AUTOSAR XML (schema 4-2-2)
package /STELLANTIS/EPT/ASWCs
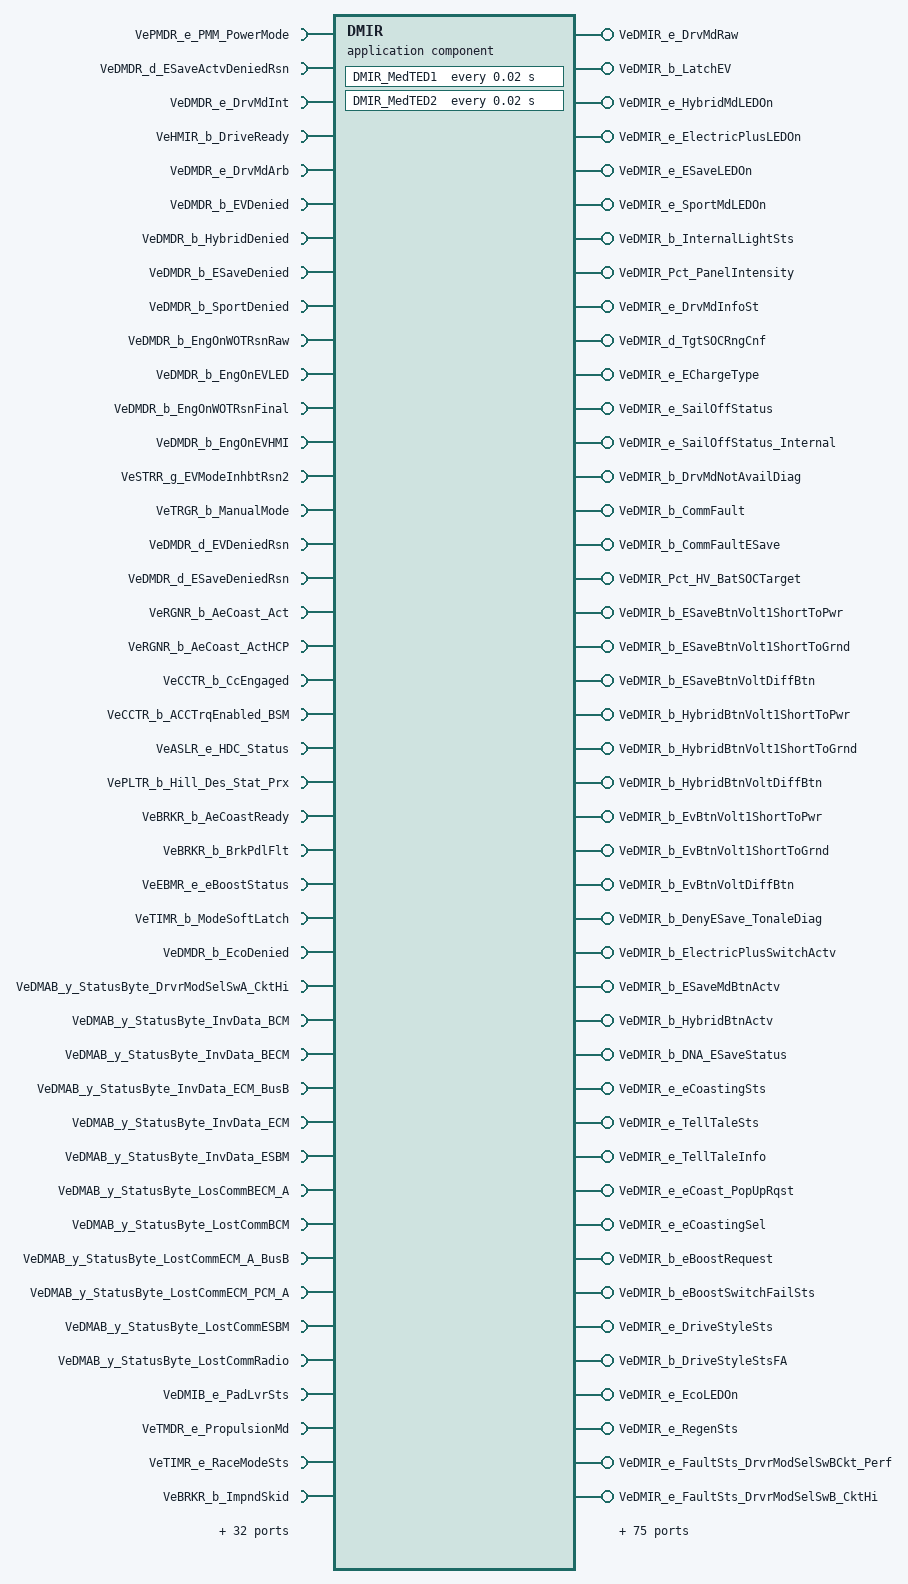
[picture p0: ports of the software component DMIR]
  application sw component type DMIR
    65 x require port:
      VePMDR_e_PMM_PowerMode: nonqueued-receiver-com-spec{data-element=Value, init-value=CePMDR_e_PowerMode_Off}, required-interface=VePMDR_e_PMM_PowerMode
      VeDMDR_d_ESaveActvDeniedRsn: nonqueued-receiver-com-spec{data-element=Value, init-value=0}, required-interface=VeDMDR_d_ESaveActvDeniedRsn
      VeDMDR_e_DrvMdInt: nonqueued-receiver-com-spec{data-element=Value, init-value=CeDMDR_e_NoDrvMd}, required-interface=VeDMDR_e_DrvMdInt
      VeHMIR_b_DriveReady: nonqueued-receiver-com-spec{data-element=Value, init-value=0}, required-interface=VeHMIR_b_DriveReady
      VeDMDR_e_DrvMdArb: nonqueued-receiver-com-spec{data-element=Value, init-value=CeDMDR_e_NoDrvMd}, required-interface=VeDMDR_e_DrvMdArb
      VeDMDR_b_EVDenied: nonqueued-receiver-com-spec{data-element=Value, init-value=0}, required-interface=VeDMDR_b_EVDenied
      VeDMDR_b_HybridDenied: nonqueued-receiver-com-spec{data-element=Value, init-value=0}, required-interface=VeDMDR_b_HybridDenied
      VeDMDR_b_ESaveDenied: nonqueued-receiver-com-spec{data-element=Value, init-value=0}, required-interface=VeDMDR_b_ESaveDenied
      VeDMDR_b_SportDenied: nonqueued-receiver-com-spec{data-element=Value, init-value=0}, required-interface=VeDMDR_b_SportDenied
      VeDMDR_b_EngOnWOTRsnRaw: nonqueued-receiver-com-spec{data-element=Value, init-value=0}, required-interface=VeDMDR_b_EngOnWOTRsnRaw
      VeDMDR_b_EngOnEVLED: nonqueued-receiver-com-spec{data-element=Value, init-value=0}, required-interface=VeDMDR_b_EngOnEVLED
      VeDMDR_b_EngOnWOTRsnFinal: nonqueued-receiver-com-spec{data-element=Value, init-value=0}, required-interface=VeDMDR_b_EngOnWOTRsnFinal
      VeDMDR_b_EngOnEVHMI: nonqueued-receiver-com-spec{data-element=Value, init-value=0}, required-interface=VeDMDR_b_EngOnEVHMI
      VeSTRR_g_EVModeInhbtRsn2: nonqueued-receiver-com-spec{data-element=Value, init-value=0}, required-interface=VeSTRR_g_EVModeInhbtRsn2
      VeTRGR_b_ManualMode: nonqueued-receiver-com-spec{data-element=Value, init-value=0}, required-interface=VeTRGR_b_ManualMode
      VeDMDR_d_EVDeniedRsn: nonqueued-receiver-com-spec{data-element=Value, init-value=0}, required-interface=VeDMDR_d_EVDeniedRsn
      VeDMDR_d_ESaveDeniedRsn: nonqueued-receiver-com-spec{data-element=Value, init-value=0}, required-interface=VeDMDR_d_ESaveDeniedRsn
      VeRGNR_b_AeCoast_Act: nonqueued-receiver-com-spec{data-element=Value, init-value=0}, required-interface=VeRGNR_b_AeCoast_Act
      VeRGNR_b_AeCoast_ActHCP: nonqueued-receiver-com-spec{data-element=Value, init-value=0}, required-interface=VeRGNR_b_AeCoast_ActHCP
      VeCCTR_b_CcEngaged: nonqueued-receiver-com-spec{data-element=Value, init-value=0}, required-interface=VeCCTR_b_CcEngaged
      VeCCTR_b_ACCTrqEnabled_BSM: nonqueued-receiver-com-spec{data-element=Value, init-value=0}, required-interface=VeCCTR_b_ACCTrqEnabled_BSM
      VeASLR_e_HDC_Status: nonqueued-receiver-com-spec{data-element=Value, init-value=CeASLR_e_HDC_UNAVL}, required-interface=VeASLR_e_HDC_Status
      VePLTR_b_Hill_Des_Stat_Prx: nonqueued-receiver-com-spec{data-element=Value, init-value=0}, required-interface=VePLTR_b_Hill_Des_Stat_Prx
      VeBRKR_b_AeCoastReady: nonqueued-receiver-com-spec{data-element=Value, init-value=0}, required-interface=VeBRKR_b_AeCoastReady
      VeBRKR_b_BrkPdlFlt: nonqueued-receiver-com-spec{data-element=Value, init-value=0}, required-interface=VeBRKR_b_BrkPdlFlt
      VeEBMR_e_eBoostStatus: nonqueued-receiver-com-spec{data-element=Value, init-value=CeEBMR_e_eBoostOFF}, required-interface=VeEBMR_e_eBoostStatus
      VeTIMR_b_ModeSoftLatch: nonqueued-receiver-com-spec{data-element=Value, init-value=0}, required-interface=VeTIMR_b_ModeSoftLatch
      VeDMDR_b_EcoDenied: nonqueued-receiver-com-spec{data-element=Value, init-value=0}, required-interface=VeDMDR_b_EcoDenied
      VeDMAB_y_StatusByte_DrvrModSelSwA_CktHi: nonqueued-receiver-com-spec{data-element=Value, init-value=0}, required-interface=VeDMAB_y_StatusByte_DrvrModSelSwA_CktHi
      VeDMAB_y_StatusByte_InvData_BCM: nonqueued-receiver-com-spec{data-element=Value, init-value=0}, required-interface=VeDMAB_y_StatusByte_InvData_BCM
      VeDMAB_y_StatusByte_InvData_BECM: nonqueued-receiver-com-spec{data-element=Value, init-value=0}, required-interface=VeDMAB_y_StatusByte_InvData_BECM
      VeDMAB_y_StatusByte_InvData_ECM_BusB: nonqueued-receiver-com-spec{data-element=Value, init-value=0}, required-interface=VeDMAB_y_StatusByte_InvData_ECM_BusB
      VeDMAB_y_StatusByte_InvData_ECM: nonqueued-receiver-com-spec{data-element=Value, init-value=0}, required-interface=VeDMAB_y_StatusByte_InvData_ECM
      VeDMAB_y_StatusByte_InvData_ESBM: nonqueued-receiver-com-spec{data-element=Value, init-value=0}, required-interface=VeDMAB_y_StatusByte_InvData_ESBM
      VeDMAB_y_StatusByte_LosCommBECM_A: nonqueued-receiver-com-spec{data-element=Value, init-value=0}, required-interface=VeDMAB_y_StatusByte_LosCommBECM_A
      VeDMAB_y_StatusByte_LostCommBCM: nonqueued-receiver-com-spec{data-element=Value, init-value=0}, required-interface=VeDMAB_y_StatusByte_LostCommBCM
      VeDMAB_y_StatusByte_LostCommECM_A_BusB: nonqueued-receiver-com-spec{data-element=Value, init-value=0}, required-interface=VeDMAB_y_StatusByte_LostCommECM_A_BusB
      VeDMAB_y_StatusByte_LostCommECM_PCM_A: nonqueued-receiver-com-spec{data-element=Value, init-value=0}, required-interface=VeDMAB_y_StatusByte_LostCommECM_PCM_A
      VeDMAB_y_StatusByte_LostCommESBM: nonqueued-receiver-com-spec{data-element=Value, init-value=0}, required-interface=VeDMAB_y_StatusByte_LostCommESBM
      VeDMAB_y_StatusByte_LostCommRadio: nonqueued-receiver-com-spec{data-element=Value, init-value=0}, required-interface=VeDMAB_y_StatusByte_LostCommRadio
      VeDMIB_e_PadLvrSts: nonqueued-receiver-com-spec{data-element=Value, init-value=CeDMIR_e_Init}, required-interface=VeDMIB_e_PadLvrSts
      VeTMDR_e_PropulsionMd: nonqueued-receiver-com-spec{data-element=Value, init-value=CeTMDR_e_NotDefine}, required-interface=VeTMDR_e_PropulsionMd
      VeTIMR_e_RaceModeSts: nonqueued-receiver-com-spec{data-element=Value, init-value=CeTIMR_e_RaceMode_Off}, required-interface=VeTIMR_e_RaceModeSts
      VeBRKR_b_ImpndSkid: nonqueued-receiver-com-spec{data-element=Value, init-value=0}, required-interface=VeBRKR_b_ImpndSkid
      VeDMDR_e_TurtleMdSts: nonqueued-receiver-com-spec{data-element=Value, init-value=CeDMDR_e_No_Turtle_Mode}, required-interface=VeDMDR_e_TurtleMdSts
      VePLTR_t_HCPOffTime: nonqueued-receiver-com-spec{data-element=Value, init-value=0}, required-interface=VePLTR_t_HCPOffTime
      VeDFIR_b_IsDiagGlobalConditionsValid: nonqueued-receiver-com-spec{data-element=Value, init-value=0}, required-interface=VeDFIR_b_IsDiagGlobalConditionsValid
      VeDMAB_y_StatusByte_DrvrModSelSwA_CktLo: nonqueued-receiver-com-spec{data-element=Value, init-value=0}, required-interface=VeDMAB_y_StatusByte_DrvrModSelSwA_CktLo
      VeDMAB_y_StatusByte_DrvrModSelSwA_CktPerf: nonqueued-receiver-com-spec{data-element=Value, init-value=0}, required-interface=VeDMAB_y_StatusByte_DrvrModSelSwA_CktPerf
      VeDMAB_y_StatusByte_DrvrModSelSwB_CktHi: nonqueued-receiver-com-spec{data-element=Value, init-value=0}, required-interface=VeDMAB_y_StatusByte_DrvrModSelSwB_CktHi
      VeDMAB_y_StatusByte_DrvrModSelSwB_CktLo: nonqueued-receiver-com-spec{data-element=Value, init-value=0}, required-interface=VeDMAB_y_StatusByte_DrvrModSelSwB_CktLo
      VeDMAB_y_StatusByte_DrvrModSelSwBCkt_Perf: nonqueued-receiver-com-spec{data-element=Value, init-value=0}, required-interface=VeDMAB_y_StatusByte_DrvrModSelSwBCkt_Perf
      VeDMAB_y_StatusByte_EcoModSwHi: nonqueued-receiver-com-spec{data-element=Value, init-value=0}, required-interface=VeDMAB_y_StatusByte_EcoModSwHi
      VeDMAB_y_StatusByte_EcoModSwLo: nonqueued-receiver-com-spec{data-element=Value, init-value=0}, required-interface=VeDMAB_y_StatusByte_EcoModSwLo
      VeDMAB_y_StatusByte_EcoModSwPerf: nonqueued-receiver-com-spec{data-element=Value, init-value=0}, required-interface=VeDMAB_y_StatusByte_EcoModSwPerf
      VeVTXR_e_PowerPanelMd: nonqueued-receiver-com-spec{data-element=Value, init-value=CeVTXR_e_DefaultMd}, required-interface=VeVTXR_e_PowerPanelMd
      VeAECR_e_AeCoastStat: nonqueued-receiver-com-spec{data-element=Value, init-value=CeAECR_e_AecoastingTemporarily_Unavailable}, required-interface=VeAECR_e_AeCoastStat
      VePLTR_e_ACCSystemSts: nonqueued-receiver-com-spec{data-element=Value, init-value=CePLTR_e_Off}, required-interface=VePLTR_e_ACCSystemSts
      VeCSVR_v_VehSpdSigned: nonqueued-receiver-com-spec{data-element=Value, init-value=0}, required-interface=VeCSVR_v_VehSpdSigned
      VeBRKR_Pct_BrkTravelSts: nonqueued-receiver-com-spec{data-element=Value, init-value=0}, required-interface=VeBRKR_Pct_BrkTravelSts
      VeDTRR_e_OPD_Sts: nonqueued-receiver-com-spec{data-element=Value, init-value=CeDTRR_e_Available}, required-interface=VeDTRR_e_OPD_Sts
      VeTRGR_e_VldtdTransRngSt: nonqueued-receiver-com-spec{data-element=Value, init-value=CeTRGR_e_NoSelectionAvailable}, required-interface=VeTRGR_e_VldtdTransRngSt
      VeDMDR_d_EcoDeniedRsn: nonqueued-receiver-com-spec{data-element=Value, init-value=0}, required-interface=VeDMDR_d_EcoDeniedRsn
      VeVSMR_e_VirtShftMd: nonqueued-receiver-com-spec{data-element=Value, init-value=CeVSMR_e_VS_Enabled}, required-interface=VeVSMR_e_VirtShftMd
      VeVSMR_e_VirtShftMdPopUp: nonqueued-receiver-com-spec{data-element=Value, init-value=CeVSMR_e_MSG_NoIssue}, required-interface=VeVSMR_e_VirtShftMdPopUp
    108 x provide port:
      VeDMIR_e_DrvMdRaw: nonqueued-sender-com-spec{data-element=Value, init-value=CeDMDR_e_NoDrvMd}, provided-interface=VeDMIR_e_DrvMdRaw
      VeDMIR_b_LatchEV: nonqueued-sender-com-spec{data-element=Value, init-value=0}, provided-interface=VeDMIR_b_LatchEV
      VeDMIR_e_HybridMdLEDOn: nonqueued-sender-com-spec{data-element=Value, init-value=CeDMDR_e_LEDOff}, provided-interface=VeDMIR_e_HybridMdLEDOn
      VeDMIR_e_ElectricPlusLEDOn: nonqueued-sender-com-spec{data-element=Value, init-value=CeDMDR_e_LEDOff}, provided-interface=VeDMIR_e_ElectricPlusLEDOn
      VeDMIR_e_ESaveLEDOn: nonqueued-sender-com-spec{data-element=Value, init-value=CeDMDR_e_LEDOff}, provided-interface=VeDMIR_e_ESaveLEDOn
      VeDMIR_e_SportMdLEDOn: nonqueued-sender-com-spec{data-element=Value, init-value=CeDMDR_e_LEDOff}, provided-interface=VeDMIR_e_SportMdLEDOn
      VeDMIR_b_InternalLightSts: nonqueued-sender-com-spec{data-element=Value, init-value=0}, provided-interface=VeDMIR_b_InternalLightSts
      VeDMIR_Pct_PanelIntensity: nonqueued-sender-com-spec{data-element=Value, init-value=0}, provided-interface=VeDMIR_Pct_PanelIntensity
      VeDMIR_e_DrvMdInfoSt: nonqueued-sender-com-spec{data-element=Value, init-value=CeDMIR_e_NoDrvMdSt}, provided-interface=VeDMIR_e_DrvMdInfoSt
      VeDMIR_d_TgtSOCRngCnf: nonqueued-sender-com-spec{data-element=Value, init-value=0}, provided-interface=VeDMIR_d_TgtSOCRngCnf
      VeDMIR_e_EChargeType: nonqueued-sender-com-spec{data-element=Value, init-value=CeDMDR_e_Passive_Charging}, provided-interface=VeDMIR_e_EChargeType
      VeDMIR_e_SailOffStatus: nonqueued-sender-com-spec{data-element=Value, init-value=CeDMDR_e_NotActive}, provided-interface=VeDMIR_e_SailOffStatus
      VeDMIR_e_SailOffStatus_Internal: nonqueued-sender-com-spec{data-element=Value, init-value=CeDMDR_e_NotActive}, provided-interface=VeDMIR_e_SailOffStatus_Internal
      VeDMIR_b_DrvMdNotAvailDiag: nonqueued-sender-com-spec{data-element=Value, init-value=0}, provided-interface=VeDMIR_b_DrvMdNotAvailDiag
      VeDMIR_b_CommFault: nonqueued-sender-com-spec{data-element=Value, init-value=0}, provided-interface=VeDMIR_b_CommFault
      VeDMIR_b_CommFaultESave: nonqueued-sender-com-spec{data-element=Value, init-value=0}, provided-interface=VeDMIR_b_CommFaultESave
      VeDMIR_Pct_HV_BatSOCTarget: nonqueued-sender-com-spec{data-element=Value, init-value=0}, provided-interface=VeDMIR_Pct_HV_BatSOCTarget
      VeDMIR_b_ESaveBtnVolt1ShortToPwr: nonqueued-sender-com-spec{data-element=Value, init-value=0}, provided-interface=VeDMIR_b_ESaveBtnVolt1ShortToPwr
      VeDMIR_b_ESaveBtnVolt1ShortToGrnd: nonqueued-sender-com-spec{data-element=Value, init-value=0}, provided-interface=VeDMIR_b_ESaveBtnVolt1ShortToGrnd
      VeDMIR_b_ESaveBtnVoltDiffBtn: nonqueued-sender-com-spec{data-element=Value, init-value=0}, provided-interface=VeDMIR_b_ESaveBtnVoltDiffBtn
      VeDMIR_b_HybridBtnVolt1ShortToPwr: nonqueued-sender-com-spec{data-element=Value, init-value=0}, provided-interface=VeDMIR_b_HybridBtnVolt1ShortToPwr
      VeDMIR_b_HybridBtnVolt1ShortToGrnd: nonqueued-sender-com-spec{data-element=Value, init-value=0}, provided-interface=VeDMIR_b_HybridBtnVolt1ShortToGrnd
      VeDMIR_b_HybridBtnVoltDiffBtn: nonqueued-sender-com-spec{data-element=Value, init-value=0}, provided-interface=VeDMIR_b_HybridBtnVoltDiffBtn
      VeDMIR_b_EvBtnVolt1ShortToPwr: nonqueued-sender-com-spec{data-element=Value, init-value=0}, provided-interface=VeDMIR_b_EvBtnVolt1ShortToPwr
      VeDMIR_b_EvBtnVolt1ShortToGrnd: nonqueued-sender-com-spec{data-element=Value, init-value=0}, provided-interface=VeDMIR_b_EvBtnVolt1ShortToGrnd
      VeDMIR_b_EvBtnVoltDiffBtn: nonqueued-sender-com-spec{data-element=Value, init-value=0}, provided-interface=VeDMIR_b_EvBtnVoltDiffBtn
      VeDMIR_b_DenyESave_TonaleDiag: nonqueued-sender-com-spec{data-element=Value, init-value=0}, provided-interface=VeDMIR_b_DenyESave_TonaleDiag
      VeDMIR_b_ElectricPlusSwitchActv: nonqueued-sender-com-spec{data-element=Value, init-value=0}, provided-interface=VeDMIR_b_ElectricPlusSwitchActv
      VeDMIR_b_ESaveMdBtnActv: nonqueued-sender-com-spec{data-element=Value, init-value=0}, provided-interface=VeDMIR_b_ESaveMdBtnActv
      VeDMIR_b_HybridBtnActv: nonqueued-sender-com-spec{data-element=Value, init-value=0}, provided-interface=VeDMIR_b_HybridBtnActv
      VeDMIR_b_DNA_ESaveStatus: nonqueued-sender-com-spec{data-element=Value, init-value=0}, provided-interface=VeDMIR_b_DNA_ESaveStatus
      VeDMIR_e_eCoastingSts: nonqueued-sender-com-spec{data-element=Value, init-value=CeDMIR_e_NotAvailable}, provided-interface=VeDMIR_e_eCoastingSts
      VeDMIR_e_TellTaleSts: nonqueued-sender-com-spec{data-element=Value, init-value=CeDMIR_e_Level1Sts}, provided-interface=VeDMIR_e_TellTaleSts
      VeDMIR_e_TellTaleInfo: nonqueued-sender-com-spec{data-element=Value, init-value=CeDMIR_e_InfoLevel1}, provided-interface=VeDMIR_e_TellTaleInfo
      VeDMIR_e_eCoast_PopUpRqst: nonqueued-sender-com-spec{data-element=Value, init-value=CeDMIR_e_InfoLevel1}, provided-interface=VeDMIR_e_eCoast_PopUpRqst
      VeDMIR_e_eCoastingSel: nonqueued-sender-com-spec{data-element=Value, init-value=CeDMIR_e_Level1}, provided-interface=VeDMIR_e_eCoastingSel
      VeDMIR_b_eBoostRequest: nonqueued-sender-com-spec{data-element=Value, init-value=0}, provided-interface=VeDMIR_b_eBoostRequest
      VeDMIR_b_eBoostSwitchFailSts: nonqueued-sender-com-spec{data-element=Value, init-value=0}, provided-interface=VeDMIR_b_eBoostSwitchFailSts
      VeDMIR_e_DriveStyleSts: nonqueued-sender-com-spec{data-element=Value, init-value=CeDMIR_e_Normal}, provided-interface=VeDMIR_e_DriveStyleSts
      VeDMIR_b_DriveStyleStsFA: nonqueued-sender-com-spec{data-element=Value, init-value=0}, provided-interface=VeDMIR_b_DriveStyleStsFA
      VeDMIR_e_EcoLEDOn: nonqueued-sender-com-spec{data-element=Value, init-value=CeDMDR_e_LEDOff}, provided-interface=VeDMIR_e_EcoLEDOn
      VeDMIR_e_RegenSts: nonqueued-sender-com-spec{data-element=Value, init-value=CeDMIR_e_NormalRegen}, provided-interface=VeDMIR_e_RegenSts
      VeDMIR_e_FaultSts_DrvrModSelSwBCkt_Perf: nonqueued-sender-com-spec{data-element=Value, init-value=CeDFIB_e_Init}, provided-interface=VeDMIR_e_FaultSts_DrvrModSelSwBCkt_Perf
      VeDMIR_e_FaultSts_DrvrModSelSwB_CktHi: nonqueued-sender-com-spec{data-element=Value, init-value=CeDFIB_e_Init}, provided-interface=VeDMIR_e_FaultSts_DrvrModSelSwB_CktHi
      VeDMIR_e_FaultSts_DrvrModSelSwB_CktLo: nonqueued-sender-com-spec{data-element=Value, init-value=CeDFIB_e_Init}, provided-interface=VeDMIR_e_FaultSts_DrvrModSelSwB_CktLo
      VeDMIR_e_FaultSts_DrvrModSelSwA_CktHi: nonqueued-sender-com-spec{data-element=Value, init-value=CeDFIB_e_Init}, provided-interface=VeDMIR_e_FaultSts_DrvrModSelSwA_CktHi
      VeDMIR_e_FaultSts_DrvrModSelSwA_CktLo: nonqueued-sender-com-spec{data-element=Value, init-value=CeDFIB_e_Init}, provided-interface=VeDMIR_e_FaultSts_DrvrModSelSwA_CktLo
      VeDMIR_e_FaultSts_DrvrModSelSwA_CktPerf: nonqueued-sender-com-spec{data-element=Value, init-value=CeDFIB_e_Init}, provided-interface=VeDMIR_e_FaultSts_DrvrModSelSwA_CktPerf
      VeDMIR_e_FaultSts_EcoModSwHi: nonqueued-sender-com-spec{data-element=Value, init-value=CeDFIB_e_Init}, provided-interface=VeDMIR_e_FaultSts_EcoModSwHi
      VeDMIR_e_FaultSts_EcoModSwLo: nonqueued-sender-com-spec{data-element=Value, init-value=CeDFIB_e_Init}, provided-interface=VeDMIR_e_FaultSts_EcoModSwLo
      VeDMIR_e_FaultSts_EcoModSwPerf: nonqueued-sender-com-spec{data-element=Value, init-value=CeDFIB_e_Init}, provided-interface=VeDMIR_e_FaultSts_EcoModSwPerf
      VeDMIR_e_CreepSts: nonqueued-sender-com-spec{data-element=Value, init-value=CeDMIR_e_CreepOff}, provided-interface=VeDMIR_e_CreepSts
      VeDMIR_e_EcoLEDOn_LIN: nonqueued-sender-com-spec{data-element=Value, init-value=CeDMDR_e_LEDOff}, provided-interface=VeDMIR_e_EcoLEDOn_LIN
      VeDMIR_e_ElectricPlusLEDOn_LIN: nonqueued-sender-com-spec{data-element=Value, init-value=CeDMDR_e_LEDOff}, provided-interface=VeDMIR_e_ElectricPlusLEDOn_LIN
      VeDMIR_e_ESaveLEDOn_LIN: nonqueued-sender-com-spec{data-element=Value, init-value=CeDMDR_e_LEDOff}, provided-interface=VeDMIR_e_ESaveLEDOn_LIN
      VeDMIR_e_PaddleModeSts: nonqueued-sender-com-spec{data-element=Value, init-value=CeDMIR_e_None}, provided-interface=VeDMIR_e_PaddleModeSts
      VeDMIR_y_eCoastingPopupMsg: nonqueued-sender-com-spec{data-element=Value, init-value=CeDMIR_e_Msg0}, provided-interface=VeDMIR_y_eCoastingPopupMsg
      VeDMIR_b_eRuptRequest: nonqueued-sender-com-spec{data-element=Value, init-value=0}, provided-interface=VeDMIR_b_eRuptRequest
      VeDMIR_e_BrakingMdReq: nonqueued-sender-com-spec{data-element=Value, init-value=CeDMIR_e_BtnNotPrsd}, provided-interface=VeDMIR_e_BrakingMdReq
      FsftDMIR_Pct_HV_BatSOCTarget: server-com-spec=FsftDMIR_Pct_HV_BatSOCTarget, provided-interface=FsftDMIR_Pct_HV_BatSOCTarget
      FsftDMIR_Pct_HV_BatSOCTarget_GGGC: server-com-spec=FsftDMIR_Pct_HV_BatSOCTarget_GGGC, provided-interface=FsftDMIR_Pct_HV_BatSOCTarget_GGGC
      FsftDMIR_Pct_PanelIntensity: server-com-spec=FsftDMIR_Pct_PanelIntensity, provided-interface=FsftDMIR_Pct_PanelIntensity
      FsftDMIR_b_DrvMdReqErr: server-com-spec=FsftDMIR_b_DrvMdReqErr, provided-interface=FsftDMIR_b_DrvMdReqErr
      FsftDMIR_b_EcoBtnSt: server-com-spec=FsftDMIR_b_EcoBtnSt, provided-interface=FsftDMIR_b_EcoBtnSt
      FsftDMIR_b_EcoBtnStLIN: server-com-spec=FsftDMIR_b_EcoBtnStLIN, provided-interface=FsftDMIR_b_EcoBtnStLIN
      FsftDMIR_b_ElectricPlusSwitchLIN: server-com-spec=FsftDMIR_b_ElectricPlusSwitchLIN, provided-interface=FsftDMIR_b_ElectricPlusSwitchLIN
      FsftDMIR_b_InternalLightSts: server-com-spec=FsftDMIR_b_InternalLightSts, provided-interface=FsftDMIR_b_InternalLightSts
      FsftDMIR_b_PaddlesFailSts: server-com-spec=FsftDMIR_b_PaddlesFailSts, provided-interface=FsftDMIR_b_PaddlesFailSts
      FsftDMIR_b_PaddlesSts: server-com-spec=FsftDMIR_b_PaddlesSts, provided-interface=FsftDMIR_b_PaddlesSts
      FsftDMIR_b_SportStatus: server-com-spec=FsftDMIR_b_SportStatus, provided-interface=FsftDMIR_b_SportStatus
      FsftDMIR_b_eDriveModeSwitchRqst: server-com-spec=FsftDMIR_b_eDriveModeSwitchRqst, provided-interface=FsftDMIR_b_eDriveModeSwitchRqst
      FsftDMIR_e_Braking_Mode_Req: server-com-spec=FsftDMIR_e_Braking_Mode_Req, provided-interface=FsftDMIR_e_Braking_Mode_Req
      FsftDMIR_e_DriveStyleSts: server-com-spec=FsftDMIR_e_DriveStyleSts, provided-interface=FsftDMIR_e_DriveStyleSts
      FsftDMIR_e_DrvMdDrvrInput: server-com-spec=FsftDMIR_e_DrvMdDrvrInput, provided-interface=FsftDMIR_e_DrvMdDrvrInput
      FsftDMIR_e_EChargetype: server-com-spec=FsftDMIR_e_EChargetype, provided-interface=FsftDMIR_e_EChargetype
      FsftDMIR_e_EChargetype_GGGC: server-com-spec=FsftDMIR_e_EChargetype_GGGC, provided-interface=FsftDMIR_e_EChargetype_GGGC
      FsftDMIR_e_ESaveBtnSt: server-com-spec=FsftDMIR_e_ESaveBtnSt, provided-interface=FsftDMIR_e_ESaveBtnSt
      FsftDMIR_e_ESaveBtnSt_CAN: server-com-spec=FsftDMIR_e_ESaveBtnSt_CAN, provided-interface=FsftDMIR_e_ESaveBtnSt_CAN
      FsftDMIR_e_EVBtnSt: server-com-spec=FsftDMIR_e_EVBtnSt, provided-interface=FsftDMIR_e_EVBtnSt
      PokeDMIR_Pct_HV_BatSOCTarget: server-com-spec{operation=PokeDMIR_Pct_HV_BatSOCTarget, queue-length=1}, provided-interface=PokeDMIR_Pct_HV_BatSOCTarget
      PokeDMIR_Pct_HV_BatSOCTarget_GGGC: server-com-spec{operation=PokeDMIR_Pct_HV_BatSOCTarget_GGGC, queue-length=1}, provided-interface=PokeDMIR_Pct_HV_BatSOCTarget_GGGC
      PokeDMIR_Pct_PanelIntensity: server-com-spec{operation=PokeDMIR_Pct_PanelIntensity, queue-length=1}, provided-interface=PokeDMIR_Pct_PanelIntensity
      PokeDMIR_b_DrvMdReqErr: server-com-spec{operation=PokeDMIR_b_DrvMdReqErr, queue-length=1}, provided-interface=PokeDMIR_b_DrvMdReqErr
      PokeDMIR_b_ESCOffActv: server-com-spec{operation=PokeDMIR_b_ESCOffActv, queue-length=1}, provided-interface=PokeDMIR_b_ESCOffActv
      PokeDMIR_b_InternalLightSts: server-com-spec{operation=PokeDMIR_b_InternalLightSts, queue-length=1}, provided-interface=PokeDMIR_b_InternalLightSts
      PokeDMIR_b_PaddlesFailSts: server-com-spec{operation=PokeDMIR_b_PaddlesFailSts, queue-length=1}, provided-interface=PokeDMIR_b_PaddlesFailSts
      PokeDMIR_b_SailOff_Request: server-com-spec{operation=PokeDMIR_b_SailOff_Request, queue-length=1}, provided-interface=PokeDMIR_b_SailOff_Request
      PokeDMIR_b_SportStatus: server-com-spec{operation=PokeDMIR_b_SportStatus, queue-length=1}, provided-interface=PokeDMIR_b_SportStatus
      PokeDMIR_e_BrakingMdReq: server-com-spec{operation=PokeDMIR_e_BrakingMdReq, queue-length=1}, provided-interface=PokeDMIR_e_BrakingMdReq
      PokeDMIR_e_CFGFeature: server-com-spec{operation=PokeDMIR_e_CFGFeature, queue-length=1}, provided-interface=PokeDMIR_e_CFGFeature
      PokeDMIR_e_CFG_Set: server-com-spec{operation=PokeDMIR_e_CFG_Set, queue-length=1}, provided-interface=PokeDMIR_e_CFG_Set
      PokeDMIR_e_CreepSts: server-com-spec{operation=PokeDMIR_e_CreepSts, queue-length=1}, provided-interface=PokeDMIR_e_CreepSts
      PokeDMIR_e_DriveStyleSts: server-com-spec{operation=PokeDMIR_e_DriveStyleSts, queue-length=1}, provided-interface=PokeDMIR_e_DriveStyleSts
      PokeDMIR_e_DrvMdDrvrInput: server-com-spec{operation=PokeDMIR_e_DrvMdDrvrInput, queue-length=1}, provided-interface=PokeDMIR_e_DrvMdDrvrInput
      PokeDMIR_e_EChargetype: server-com-spec{operation=PokeDMIR_e_EChargetype, queue-length=1}, provided-interface=PokeDMIR_e_EChargetype
      PokeDMIR_e_EChargetype_GGGC: server-com-spec{operation=PokeDMIR_e_EChargetype_GGGC, queue-length=1}, provided-interface=PokeDMIR_e_EChargetype_GGGC
      PokeDMIR_e_ECoastingReq: server-com-spec{operation=PokeDMIR_e_ECoastingReq, queue-length=1}, provided-interface=PokeDMIR_e_ECoastingReq
      PokeDMIR_e_EcoBtnSt: server-com-spec{operation=PokeDMIR_e_EcoBtnSt, queue-length=1}, provided-interface=PokeDMIR_e_EcoBtnSt
      PokeDMIR_e_EcoBtnStLIN: server-com-spec{operation=PokeDMIR_e_EcoBtnStLIN, queue-length=1}, provided-interface=PokeDMIR_e_EcoBtnStLIN
      PokeDMIR_e_ElectricPlusSwitch: server-com-spec{operation=PokeDMIR_e_ElectricPlusSwitch, queue-length=1}, provided-interface=PokeDMIR_e_ElectricPlusSwitch
      PokeDMIR_e_ElectricPlusSwitchLIN: server-com-spec{operation=PokeDMIR_e_ElectricPlusSwitchLIN, queue-length=1}, provided-interface=PokeDMIR_e_ElectricPlusSwitchLIN
      PokeDMIR_e_PaddleModeReq: server-com-spec{operation=PokeDMIR_e_PaddleModeReq, queue-length=1}, provided-interface=PokeDMIR_e_PaddleModeReq
      PokeDMIR_e_PaddlesSts: server-com-spec{operation=PokeDMIR_e_PaddlesSts, queue-length=1}, provided-interface=PokeDMIR_e_PaddlesSts
      PokeDMIR_e_PowershotSts: server-com-spec{operation=PokeDMIR_e_PowershotSts, queue-length=1}, provided-interface=PokeDMIR_e_PowershotSts
      PokeDMIR_e_StReq: server-com-spec{operation=PokeDMIR_e_StReq, queue-length=1}, provided-interface=PokeDMIR_e_StReq
      PokeDMIR_e_eDriveModeSwitchRqst: server-com-spec{operation=PokeDMIR_e_eDriveModeSwitchRqst, queue-length=1}, provided-interface=PokeDMIR_e_eDriveModeSwitchRqst
      PokeDMIR_e_eSaveSwitch: server-com-spec{operation=PokeDMIR_e_eSaveSwitch, queue-length=1}, provided-interface=PokeDMIR_e_eSaveSwitch
      PokeDMIR_e_eSaveSwitchLIN: server-com-spec{operation=PokeDMIR_e_eSaveSwitchLIN, queue-length=1}, provided-interface=PokeDMIR_e_eSaveSwitchLIN
    11 x require port:
      NeDMIR_e_eCoastLvlLatched_Rx: nv-require-com-spec{init-value=CeDMIR_e_NotAvail, variable=NeDMIR_e_eCoastLvlLatched}, required-interface=NeDMIR_e_eCoastLvlLatched
      EeDMIR_d_ChargeTypeCnf_Rx: nv-require-com-spec{init-value=0, variable=EeDMIR_d_ChargeTypeCnf}, required-interface=EeDMIR_d_ChargeTypeCnf
      EeDMIR_d_TgtSOCRngCnf_Rx: nv-require-com-spec{init-value=0, variable=EeDMIR_d_TgtSOCRngCnf}, required-interface=EeDMIR_d_TgtSOCRngCnf
      NeDMIR_e_DrvMdArb_Rx: nv-require-com-spec{init-value=0, variable=NeDMIR_e_DrvMdArb}, required-interface=NeDMIR_e_DrvMdArb
      NeDMIR_e_DriveStyleSts_Rx: nv-require-com-spec{init-value=0, variable=NeDMIR_e_DriveStyleSts}, required-interface=NeDMIR_e_DriveStyleSts
      NeDMIR_e_RegenSts_Rx: nv-require-com-spec{init-value=CeDMIR_e_NormalRegen, variable=NeDMIR_e_RegenSts}, required-interface=NeDMIR_e_RegenSts
      NeDMIR_e_eCoastDefaultAuto_Rx: nv-require-com-spec{init-value=CeDMIR_e_Level1, variable=NeDMIR_e_eCoastDefaultAuto}, required-interface=NeDMIR_e_eCoastDefaultAuto
      NeDMIR_e_eCoastDefaultCustom_Rx: nv-require-com-spec{init-value=CeDMIR_e_Level1, variable=NeDMIR_e_eCoastDefaultCustom}, required-interface=NeDMIR_e_eCoastDefaultCustom
      NeDMIR_e_CreepSts_Rx: nv-require-com-spec{init-value=CeDMIR_e_CreepOff, variable=NeDMIR_e_CreepSts}, required-interface=NeDMIR_e_CreepSts
      NeDMIR_e_RaceModeSts_Rx: nv-require-com-spec{init-value=CeTIMR_e_RaceMode_Off, variable=NeDMIR_e_RaceModeSts}, required-interface=NeDMIR_e_RaceModeSts
      NeDMIR_e_PddlMdStatus_Rx: nv-require-com-spec{init-value=CeDMIR_e_En, variable=NeDMIR_e_PddlMdStatus}, required-interface=NeDMIR_e_PddlMdStatus
    11 x provide port:
      NeDMIR_e_eCoastLvlLatched: nv-provide-com-spec{ram-block-init-value=CeDMIR_e_NotAvail, variable=NeDMIR_e_eCoastLvlLatched}, provided-interface=NeDMIR_e_eCoastLvlLatched
      EeDMIR_d_ChargeTypeCnf: nv-provide-com-spec{ram-block-init-value=0, variable=EeDMIR_d_ChargeTypeCnf}, provided-interface=EeDMIR_d_ChargeTypeCnf
      EeDMIR_d_TgtSOCRngCnf: nv-provide-com-spec{ram-block-init-value=0, variable=EeDMIR_d_TgtSOCRngCnf}, provided-interface=EeDMIR_d_TgtSOCRngCnf
      NeDMIR_e_DrvMdArb: nv-provide-com-spec{ram-block-init-value=0, variable=NeDMIR_e_DrvMdArb}, provided-interface=NeDMIR_e_DrvMdArb
      NeDMIR_e_DriveStyleSts: nv-provide-com-spec{ram-block-init-value=0, variable=NeDMIR_e_DriveStyleSts}, provided-interface=NeDMIR_e_DriveStyleSts
      NeDMIR_e_RegenSts: nv-provide-com-spec{ram-block-init-value=CeDMIR_e_NormalRegen, variable=NeDMIR_e_RegenSts}, provided-interface=NeDMIR_e_RegenSts
      NeDMIR_e_eCoastDefaultAuto: nv-provide-com-spec{ram-block-init-value=CeDMIR_e_Level1, variable=NeDMIR_e_eCoastDefaultAuto}, provided-interface=NeDMIR_e_eCoastDefaultAuto
      NeDMIR_e_eCoastDefaultCustom: nv-provide-com-spec{ram-block-init-value=CeDMIR_e_Level1, variable=NeDMIR_e_eCoastDefaultCustom}, provided-interface=NeDMIR_e_eCoastDefaultCustom
      NeDMIR_e_CreepSts: nv-provide-com-spec{ram-block-init-value=CeDMIR_e_CreepOff, variable=NeDMIR_e_CreepSts}, provided-interface=NeDMIR_e_CreepSts
      NeDMIR_e_RaceModeSts: nv-provide-com-spec{ram-block-init-value=CeTIMR_e_RaceMode_Off, variable=NeDMIR_e_RaceModeSts}, provided-interface=NeDMIR_e_RaceModeSts
      NeDMIR_e_PddlMdStatus: nv-provide-com-spec{ram-block-init-value=CeDMIR_e_En, variable=NeDMIR_e_PddlMdStatus}, provided-interface=NeDMIR_e_PddlMdStatus
    behavior IB_DMIR: data-type-mapping=msADTtoIDTMapping, handle-termination-and-restart=NO-SUPPORT, included-data-type-set=data-type=[TeDMIR_e_DiagStatus, TeDMIR_e_StuckDiagStatus]
      timing event Event_MedTED1: start-on-event=DMIR_MedTED1, period=0.02
      timing event Event_MedTED2: start-on-event=DMIR_MedTED2, period=0.02
      48 x operation invoked event:
        Event_FsftDMIR_Pct_HV_BatSOCTarget: start-on-event=FsftDMIR_Pct_HV_BatSOCTarget, operation=FsftDMIR_Pct_HV_BatSOCTarget.FsftDMIR_Pct_HV_BatSOCTarget
        Event_FsftDMIR_Pct_HV_BatSOCTarget_GGGC: start-on-event=FsftDMIR_Pct_HV_BatSOCTarget_GGGC, operation=FsftDMIR_Pct_HV_BatSOCTarget_GGGC.FsftDMIR_Pct_HV_BatSOCTarget_GGGC
        Event_FsftDMIR_Pct_PanelIntensity: start-on-event=FsftDMIR_Pct_PanelIntensity, operation=FsftDMIR_Pct_PanelIntensity.FsftDMIR_Pct_PanelIntensity
        Event_FsftDMIR_b_DrvMdReqErr: start-on-event=FsftDMIR_b_DrvMdReqErr, operation=FsftDMIR_b_DrvMdReqErr.FsftDMIR_b_DrvMdReqErr
        Event_FsftDMIR_b_EcoBtnSt: start-on-event=FsftDMIR_b_EcoBtnSt, operation=FsftDMIR_b_EcoBtnSt.FsftDMIR_b_EcoBtnSt
        Event_FsftDMIR_b_EcoBtnStLIN: start-on-event=FsftDMIR_b_EcoBtnStLIN, operation=FsftDMIR_b_EcoBtnStLIN.FsftDMIR_b_EcoBtnStLIN
        Event_FsftDMIR_b_ElectricPlusSwitchLIN: start-on-event=FsftDMIR_b_ElectricPlusSwitchLIN, operation=FsftDMIR_b_ElectricPlusSwitchLIN.FsftDMIR_b_ElectricPlusSwitchLIN
        Event_FsftDMIR_b_InternalLightSts: start-on-event=FsftDMIR_b_InternalLightSts, operation=FsftDMIR_b_InternalLightSts.FsftDMIR_b_InternalLightSts
        Event_FsftDMIR_b_PaddlesFailSts: start-on-event=FsftDMIR_b_PaddlesFailSts, operation=FsftDMIR_b_PaddlesFailSts.FsftDMIR_b_PaddlesFailSts
        Event_FsftDMIR_b_PaddlesSts: start-on-event=FsftDMIR_b_PaddlesSts, operation=FsftDMIR_b_PaddlesSts.FsftDMIR_b_PaddlesSts
        Event_FsftDMIR_b_SportStatus: start-on-event=FsftDMIR_b_SportStatus, operation=FsftDMIR_b_SportStatus.FsftDMIR_b_SportStatus
        Event_FsftDMIR_b_eDriveModeSwitchRqst: start-on-event=FsftDMIR_b_eDriveModeSwitchRqst, operation=FsftDMIR_b_eDriveModeSwitchRqst.FsftDMIR_b_eDriveModeSwitchRqst
        Event_FsftDMIR_e_Braking_Mode_Req: start-on-event=FsftDMIR_e_Braking_Mode_Req, operation=FsftDMIR_e_Braking_Mode_Req.FsftDMIR_e_Braking_Mode_Req
        Event_FsftDMIR_e_DriveStyleSts: start-on-event=FsftDMIR_e_DriveStyleSts, operation=FsftDMIR_e_DriveStyleSts.FsftDMIR_e_DriveStyleSts
        Event_FsftDMIR_e_DrvMdDrvrInput: start-on-event=FsftDMIR_e_DrvMdDrvrInput, operation=FsftDMIR_e_DrvMdDrvrInput.FsftDMIR_e_DrvMdDrvrInput
        Event_FsftDMIR_e_EChargetype: start-on-event=FsftDMIR_e_EChargetype, operation=FsftDMIR_e_EChargetype.FsftDMIR_e_EChargetype
        Event_FsftDMIR_e_EChargetype_GGGC: start-on-event=FsftDMIR_e_EChargetype_GGGC, operation=FsftDMIR_e_EChargetype_GGGC.FsftDMIR_e_EChargetype_GGGC
        Event_FsftDMIR_e_ESaveBtnSt: start-on-event=FsftDMIR_e_ESaveBtnSt, operation=FsftDMIR_e_ESaveBtnSt.FsftDMIR_e_ESaveBtnSt
        Event_FsftDMIR_e_ESaveBtnSt_CAN: start-on-event=FsftDMIR_e_ESaveBtnSt_CAN, operation=FsftDMIR_e_ESaveBtnSt_CAN.FsftDMIR_e_ESaveBtnSt_CAN
        Event_FsftDMIR_e_EVBtnSt: start-on-event=FsftDMIR_e_EVBtnSt, operation=FsftDMIR_e_EVBtnSt.FsftDMIR_e_EVBtnSt
        Event_PokeDMIR_Pct_HV_BatSOCTarget: start-on-event=PokeDMIR_Pct_HV_BatSOCTarget, operation=PokeDMIR_Pct_HV_BatSOCTarget.PokeDMIR_Pct_HV_BatSOCTarget
        Event_PokeDMIR_Pct_HV_BatSOCTarget_GGGC: start-on-event=PokeDMIR_Pct_HV_BatSOCTarget_GGGC, operation=PokeDMIR_Pct_HV_BatSOCTarget_GGGC.PokeDMIR_Pct_HV_BatSOCTarget_GGGC
        Event_PokeDMIR_Pct_PanelIntensity: start-on-event=PokeDMIR_Pct_PanelIntensity, operation=PokeDMIR_Pct_PanelIntensity.PokeDMIR_Pct_PanelIntensity
        Event_PokeDMIR_b_DrvMdReqErr: start-on-event=PokeDMIR_b_DrvMdReqErr, operation=PokeDMIR_b_DrvMdReqErr.PokeDMIR_b_DrvMdReqErr
        Event_PokeDMIR_b_ESCOffActv: start-on-event=PokeDMIR_b_ESCOffActv, operation=PokeDMIR_b_ESCOffActv.PokeDMIR_b_ESCOffActv
        Event_PokeDMIR_b_InternalLightSts: start-on-event=PokeDMIR_b_InternalLightSts, operation=PokeDMIR_b_InternalLightSts.PokeDMIR_b_InternalLightSts
        Event_PokeDMIR_b_PaddlesFailSts: start-on-event=PokeDMIR_b_PaddlesFailSts, operation=PokeDMIR_b_PaddlesFailSts.PokeDMIR_b_PaddlesFailSts
        Event_PokeDMIR_b_SailOff_Request: start-on-event=PokeDMIR_b_SailOff_Request, operation=PokeDMIR_b_SailOff_Request.PokeDMIR_b_SailOff_Request
        Event_PokeDMIR_b_SportStatus: start-on-event=PokeDMIR_b_SportStatus, operation=PokeDMIR_b_SportStatus.PokeDMIR_b_SportStatus
        Event_PokeDMIR_e_BrakingMdReq: start-on-event=PokeDMIR_e_BrakingMdReq, operation=PokeDMIR_e_BrakingMdReq.PokeDMIR_e_BrakingMdReq
        Event_PokeDMIR_e_CFGFeature: start-on-event=PokeDMIR_e_CFGFeature, operation=PokeDMIR_e_CFGFeature.PokeDMIR_e_CFGFeature
        Event_PokeDMIR_e_CFG_Set: start-on-event=PokeDMIR_e_CFG_Set, operation=PokeDMIR_e_CFG_Set.PokeDMIR_e_CFG_Set
        Event_PokeDMIR_e_CreepSts: start-on-event=PokeDMIR_e_CreepSts, operation=PokeDMIR_e_CreepSts.PokeDMIR_e_CreepSts
        Event_PokeDMIR_e_DrvMdDrvrInput: start-on-event=PokeDMIR_e_DrvMdDrvrInput, operation=PokeDMIR_e_DrvMdDrvrInput.PokeDMIR_e_DrvMdDrvrInput
        Event_PokeDMIR_e_EChargetype: start-on-event=PokeDMIR_e_EChargetype, operation=PokeDMIR_e_EChargetype.PokeDMIR_e_EChargetype
        Event_PokeDMIR_e_EChargetype_GGGC: start-on-event=PokeDMIR_e_EChargetype_GGGC, operation=PokeDMIR_e_EChargetype_GGGC.PokeDMIR_e_EChargetype_GGGC
        Event_PokeDMIR_e_ECoastingReq: start-on-event=PokeDMIR_e_ECoastingReq, operation=PokeDMIR_e_ECoastingReq.PokeDMIR_e_ECoastingReq
        Event_PokeDMIR_e_EcoBtnSt: start-on-event=PokeDMIR_e_EcoBtnSt, operation=PokeDMIR_e_EcoBtnSt.PokeDMIR_e_EcoBtnSt
        Event_PokeDMIR_e_EcoBtnStLIN: start-on-event=PokeDMIR_e_EcoBtnStLIN, operation=PokeDMIR_e_EcoBtnStLIN.PokeDMIR_e_EcoBtnStLIN
        Event_PokeDMIR_e_ElectricPlusSwitch: start-on-event=PokeDMIR_e_ElectricPlusSwitch, operation=PokeDMIR_e_ElectricPlusSwitch.PokeDMIR_e_ElectricPlusSwitch
        Event_PokeDMIR_e_ElectricPlusSwitchLIN: start-on-event=PokeDMIR_e_ElectricPlusSwitchLIN, operation=PokeDMIR_e_ElectricPlusSwitchLIN.PokeDMIR_e_ElectricPlusSwitchLIN
        Event_PokeDMIR_e_PaddleModeReq: start-on-event=PokeDMIR_e_PaddleModeReq, operation=PokeDMIR_e_PaddleModeReq.PokeDMIR_e_PaddleModeReq
        Event_PokeDMIR_e_PaddlesSts: start-on-event=PokeDMIR_e_PaddlesSts, operation=PokeDMIR_e_PaddlesSts.PokeDMIR_e_PaddlesSts
        Event_PokeDMIR_e_PowershotSts: start-on-event=PokeDMIR_e_PowershotSts, operation=PokeDMIR_e_PowershotSts.PokeDMIR_e_PowershotSts
        Event_PokeDMIR_e_StReq: start-on-event=PokeDMIR_e_StReq, operation=PokeDMIR_e_StReq.PokeDMIR_e_StReq
        Event_PokeDMIR_e_eDriveModeSwitchRqst: start-on-event=PokeDMIR_e_eDriveModeSwitchRqst, operation=PokeDMIR_e_eDriveModeSwitchRqst.PokeDMIR_e_eDriveModeSwitchRqst
        Event_PokeDMIR_e_eSaveSwitch: start-on-event=PokeDMIR_e_eSaveSwitch, operation=PokeDMIR_e_eSaveSwitch.PokeDMIR_e_eSaveSwitch
        Event_PokeDMIR_e_eSaveSwitchLIN: start-on-event=PokeDMIR_e_eSaveSwitchLIN, operation=PokeDMIR_e_eSaveSwitchLIN.PokeDMIR_e_eSaveSwitchLIN
      init event Event_DMIR_ac_Init: start-on-event=DMIR_ac_Init
      init event Event_PwrOn: start-on-event=DMIR_PwrOn
      init event Event_PwrOff: start-on-event=DMIR_PwrOff
      explicit-inter-runnable-variables:
        94 x data, all with category=VALUE, sw-calibration-access=READ-ONLY:
          VeDMIR_e_DrvMdDrvrInput_write_IRV: type=UInt8, init-value=0
          VeDMIR_b_DrvMdDrvrInputFA_write_IRV: type=Boolean, init-value=0
          VeDMIR_e_EChargetype_write_IRV: type=TeDMDR_e_EChargetype, init-value=CeDMDR_e_Passive_Charging
          VeDMIR_e_EChargetypeGGGC_write_IRV: type=TeDMDR_e_EChargetype, init-value=CeDMDR_e_Passive_Charging
          VeDMIR_b_EChargetypeFA_write_IRV: type=Boolean, init-value=0
          VeDMIR_b_EChargetypeGGGCFA_write_IRV: type=Boolean, init-value=0
          VeDMIR_Pct_HV_BatSOCTarget_write_IRV: type=Float, init-value=0
          VeDMIR_Pct_HV_BatSOCTarget_GGGC_write_IRV: type=Float, init-value=0
          VeDMIR_b_HV_BatSOCTargetFA_write_IRV: type=Boolean, init-value=0
          VeDMIR_b_HV_BatSOCTarget_GGGCFA_write_IRV: type=Boolean, init-value=0
          VeDMIR_b_InternalLightSts_write_IRV: type=Boolean, init-value=0
          VeDMIR_b_InternalLightStsFA_write_IRV: type=Boolean, init-value=0
          VeDMIR_Pct_PanelIntensity_write_IRV: type=Float, init-value=0
          VeDMIR_b_PanelIntensityFA_write_IRV: type=Boolean, init-value=0
          VeDMIR_e_ElectricPlusSwitch_write_IRV: type=TeDMDR_e_DrvMdBtnStat, init-value=CeDMDR_e_BtnNotPrsd
          VeDMIR_b_EVBtnStFA_write_IRV: type=Boolean, init-value=0
          VeDMIR_e_ESaveBtnStLIN_write_IRV: type=TeDMDR_e_DrvMdBtnStat, init-value=CeDMDR_e_BtnNotPrsd
          VeDMIR_b_ESaveBtnSt_CANFA_write_IRV: type=Boolean, init-value=0
          VeDMIR_e_eSaveSwitch_write_IRV: type=TeDMDR_e_DrvMdBtnStat, init-value=CeDMDR_e_BtnNotPrsd
          VeDMIR_b_ESaveBtnStFA_write_IRV: type=Boolean, init-value=0
          VeDMIR_b_DrvMdReqErr_write_IRV: type=Boolean, init-value=0
          VeDMIR_b_DrvMdReqErrFA_write_IRV: type=Boolean, init-value=0
          VeDMIR_e_CFGFeature_write_IRV: type=SInt16, init-value=0
          VeDMIR_e_StReq_write_IRV: type=SInt16, init-value=0
          VeDMIR_e_CFG_Set_write_IRV: type=TeDMDR_e_EChargetype, init-value=CeDMDR_e_Passive_Charging
          VeDMIR_b_SailOff_Request_write_IRV: type=Boolean, init-value=0
          VeDMIR_b_ESCOffActv_write_IRV: type=Boolean, init-value=0
          VeDMIR_e_PaddleSts_write_IRV: type=TeDMIR_e_PaddlesSts, init-value=CeDMIR_e_NotActive
          VeDMIR_b_PaddlesStsFA_write_IRV: type=Boolean, init-value=0
          VeDMIR_b_PaddlesFailSts_write_IRV: type=Boolean, init-value=0
          VeDMIR_b_PaddlesFailStsFA_write_IRV: type=Boolean, init-value=0
          VeDMIR_e_eDriveModeSwitchRqst_write_IRV: type=TeDMIR_e_eDriveModeSwitchSts, init-value=CeDMIR_e_NotPressed
          VeDMIR_b_eDriveModeSwitchRqstFA_write_IRV: type=Boolean, init-value=0
          VeDMIR_b_SportStatus_write_IRV: type=Boolean, init-value=0
          VeDMIR_b_DriveStyleStsFA_write_IRV: type=Boolean, init-value=0
          VeDMIR_e_EcoBtnSt_write_IRV: type=TeDMDR_e_DrvMdBtnStat, init-value=CeDMDR_e_BtnNotPrsd
          VeDMIR_b_EcoBtnStFA_write_IRV: type=Boolean, init-value=0
          Comm_b_DrvMdDrvrInputFA_write_IRV: type=Boolean, init-value=0
          Comm_b_DrvMdReqErr_write_IRV: type=Boolean, init-value=0
          Comm_b_EVBtnFA_write_IRV: type=Boolean, init-value=0
          Comm_b_ESaveBtnFA_write_IRV: type=Boolean, init-value=0
          Comm_e_ElectricPlusSwitch_write_IRV: type=TeDMDR_e_DrvMdBtnStat, init-value=CeDMDR_e_BtnNotPrsd
          Comm_e_ESaveBtn_write_IRV: type=TeDMDR_e_DrvMdBtnStat, init-value=CeDMDR_e_BtnNotPrsd
          Comm_e_DrvMdDrvrInput_write_IRV: type=UInt8, init-value=0
          Comm_eDriveModeSwitchRqstFA_write_IRV: type=Boolean, init-value=0
          Comm_eDriveModeSwitchRqst_write_IRV: type=TeDMIR_e_eDriveModeSwitchSts, init-value=CeDMIR_e_NotPressed
          SailOff_Request_write_IRV: type=Boolean, init-value=0
          Comm_DodgeSportSts_write_IRV: type=Boolean, init-value=0
          Comm_PaddlesFailSts_write_IRV: type=Boolean, init-value=0
          Comm_PaddlesStsFA_write_IRV: type=Boolean, init-value=0
          Comm_PaddlesFailStsFA_write_IRV: type=Boolean, init-value=0
          Comm_PaddlesSts_write_IRV: type=TeDMIR_e_PaddlesSts, init-value=CeDMIR_e_NotActive
          Comm_e_DriveStyleSts_write_IRV: type=TeDMIR_e_DriveStyleSts, init-value=CeDMIR_e_Normal
          Comm_EcoBtnSt_write_IRV: type=TeDMDR_e_DrvMdBtnStat, init-value=CeDMDR_e_BtnNotPrsd
          VeDMIC_e_HybridMdLEDOn_write_IRV: type=TeDMDR_e_DrvMdLEDStat, init-value=CeDMDR_e_LEDOff
          VeDMIC_e_EVMdLEDOn_write_IRV: type=TeDMDR_e_DrvMdLEDStat, init-value=CeDMDR_e_LEDOff
          VeDMIC_e_ESaveLEDOn_write_IRV: type=TeDMDR_e_DrvMdLEDStat, init-value=CeDMDR_e_LEDOff
          VeDMIC_e_SportLEDOn_write_IRV: type=TeDMDR_e_DrvMdLEDStat, init-value=CeDMDR_e_LEDOff
          VeDMIC_b_InternalLightSts_write_IRV: type=Boolean, init-value=0
          VeDMIC_Pct_PanelIntensity_write_IRV: type=Float, init-value=0
          VeDMIC_e_DrvMdInfoSt_write_IRV: type=TeDMIR_e_DrvMdSt, init-value=CeDMIR_e_NoDrvMdSt
          VeDMDI_e_TgtSOCRngCnf_write_IRV: type=UInt16, init-value=0
          Comm_e_EChargeType_write_IRV: type=TeDMDR_e_EChargetype, init-value=CeDMDR_e_Passive_Charging
          Comm_Pct_HV_BatSOCTarget_write_IRV: type=Float, init-value=0
          Comm_b_DriveStyleStsFA_write_IRV: type=Boolean, init-value=0
          VeDMIC_b_EcoLEDOn_write_IRV: type=TeDMDR_e_DrvMdLEDStat, init-value=CeDMDR_e_LEDOff
          VeDMIR_e_ECoastingReq_IRV: type=TeDMIR_e_ECoastingReq, init-value=CeDMIR_e_LevelOne
          VeDMIR_e_PoweshotSts_IRV: type=TeDMIR_e_PowershotButton, init-value=CeDMIR_e_Not_Activated
          VeDMIR_e_ElectricPlusSwitchLIN_write_IRV: type=TeDMDR_e_DrvMdBtnStat, init-value=CeDMDR_e_BtnNotPrsd
          VeDMIR_e_EcoBtnStLIN_write_IRV: type=TeDMDR_e_DrvMdBtnStat, init-value=CeDMDR_e_BtnNotPrsd
          VeDMIR_b_ElectricPlusSwitchLINFA_write_IRV: type=Boolean, init-value=0
          VeDMIR_b_EcoBtnStLINFA_write_IRV: type=Boolean, init-value=0
          Comm_EcoBtnStFA_write_IRV: type=Boolean, init-value=0
          VeDMIR_e_PddlMdReq_IRV: type=TeDMIR_e_PaddleModeRequest, init-value=CeDMIR_e_None
          Comm_e_KeDMIR_e_BrakingMdReq_write_IRV: type=TeDMIR_e_DrvMdBtnStat, init-value=CeDMIR_e_BtnNotPrsd
          DrvMdArb_write_IRV: type=TeDMDR_e_DrvMd, init-value=CeDMDR_e_NoDrvMd
          EVModeDenied_write_IRV: type=Boolean, init-value=0
          HybridModeDenied_write_IRV: type=Boolean, init-value=0
          ESaveModeDenied_write_IRV: type=Boolean, init-value=0
          SportModeDenied_write_IRV: type=Boolean, init-value=0
          VeDMID_b_DrvMdNotAvailDiag_write_IRV: type=Boolean, init-value=0
          Comm_b_InternalLightSts_write_IRV: type=Boolean, init-value=0
          Comm_Pct_PanelIntensity_write_IRV: type=Float, init-value=0
          EngOnWOTRsnRaw_write_IRV: type=Boolean, init-value=0
          PowerMode_write_IRV: type=TePMDR_e_PowerMode, init-value=CePMDR_e_PowerMode_Off
          EngOnInEVLED_write_IRV: type=Boolean, init-value=0
          EngOnWOTRsnFnl_write_IRV: type=Boolean, init-value=0
          EngOnEVFnlHMI_write_IRV: type=Boolean, init-value=0
          DriveReady_write_IRV: type=Boolean, init-value=0
          EVModeInhibit2_write_IRV: type=UInt32, init-value=0
          VeDMID_b_HybridBtnActv_write_IRV: type=Boolean, init-value=0
          VeDMIC_e_DrvMdRaw_write_IRV: type=TeDMDR_e_DrvMd, init-value=CeDMDR_e_NoDrvMd
          DenyEsave_TonaleDiag_write_IRV: type=Boolean, init-value=0
          EcoDenied_write_IRV: type=Boolean, init-value=0
      53 x runnable:
        DMIR_ac_Init
          data-send-points:
            36 x access:
              OUT_VeDMIR_e_DrvMdRaw_Value: accessed-variable=VeDMIR_e_DrvMdRaw.Value
              OUT_VeDMIR_e_HybridMdLEDOn_Value: accessed-variable=VeDMIR_e_HybridMdLEDOn.Value
              OUT_VeDMIR_e_ElectricPlusLEDOn_Value: accessed-variable=VeDMIR_e_ElectricPlusLEDOn.Value
              OUT_VeDMIR_e_ESaveLEDOn_Value: accessed-variable=VeDMIR_e_ESaveLEDOn.Value
              OUT_VeDMIR_e_SportMdLEDOn_Value: accessed-variable=VeDMIR_e_SportMdLEDOn.Value
              OUT_VeDMIR_e_DrvMdInfoSt_Value: accessed-variable=VeDMIR_e_DrvMdInfoSt.Value
              OUT_VeDMIR_e_EChargeType_Value: accessed-variable=VeDMIR_e_EChargeType.Value
              OUT_VeDMIR_e_SailOffStatus_Value: accessed-variable=VeDMIR_e_SailOffStatus.Value
              OUT_VeDMIR_e_SailOffStatus_Internal_Value: accessed-variable=VeDMIR_e_SailOffStatus_Internal.Value
              OUT_VeDMIR_e_eCoastingSts_Value: accessed-variable=VeDMIR_e_eCoastingSts.Value
              OUT_VeDMIR_e_TellTaleSts_Value: accessed-variable=VeDMIR_e_TellTaleSts.Value
              OUT_VeDMIR_e_TellTaleInfo_Value: accessed-variable=VeDMIR_e_TellTaleInfo.Value
              OUT_VeDMIR_e_eCoast_PopUpRqst_Value: accessed-variable=VeDMIR_e_eCoast_PopUpRqst.Value
              OUT_VeDMIR_e_eCoastingSel_Value: accessed-variable=VeDMIR_e_eCoastingSel.Value
              OUT_VeDMIR_e_DriveStyleSts_Value: accessed-variable=VeDMIR_e_DriveStyleSts.Value
              OUT_VeDMIR_e_EcoLEDOn_Value: accessed-variable=VeDMIR_e_EcoLEDOn.Value
              OUT_VeDMIR_e_RegenSts_Value: accessed-variable=VeDMIR_e_RegenSts.Value
              OUT_VeDMIR_e_FaultSts_DrvrModSelSwBCkt_Perf_Value: accessed-variable=VeDMIR_e_FaultSts_DrvrModSelSwBCkt_Perf.Value
              OUT_VeDMIR_e_FaultSts_DrvrModSelSwB_CktHi_Value: accessed-variable=VeDMIR_e_FaultSts_DrvrModSelSwB_CktHi.Value
              OUT_VeDMIR_e_FaultSts_DrvrModSelSwB_CktLo_Value: accessed-variable=VeDMIR_e_FaultSts_DrvrModSelSwB_CktLo.Value
              OUT_VeDMIR_e_FaultSts_DrvrModSelSwA_CktHi_Value: accessed-variable=VeDMIR_e_FaultSts_DrvrModSelSwA_CktHi.Value
              OUT_VeDMIR_e_FaultSts_DrvrModSelSwA_CktLo_Value: accessed-variable=VeDMIR_e_FaultSts_DrvrModSelSwA_CktLo.Value
              OUT_VeDMIR_e_FaultSts_DrvrModSelSwA_CktPerf_Value: accessed-variable=VeDMIR_e_FaultSts_DrvrModSelSwA_CktPerf.Value
              OUT_VeDMIR_e_FaultSts_EcoModSwHi_Value: accessed-variable=VeDMIR_e_FaultSts_EcoModSwHi.Value
              OUT_VeDMIR_e_FaultSts_EcoModSwLo_Value: accessed-variable=VeDMIR_e_FaultSts_EcoModSwLo.Value
              OUT_VeDMIR_e_FaultSts_EcoModSwPerf_Value: accessed-variable=VeDMIR_e_FaultSts_EcoModSwPerf.Value
              OUT_VeDMIR_e_CreepSts_Value: accessed-variable=VeDMIR_e_CreepSts.Value
              OUT_VeDMIR_e_EcoLEDOn_LIN_Value: accessed-variable=VeDMIR_e_EcoLEDOn_LIN.Value
              OUT_VeDMIR_e_ElectricPlusLEDOn_LIN_Value: accessed-variable=VeDMIR_e_ElectricPlusLEDOn_LIN.Value
              OUT_VeDMIR_e_ESaveLEDOn_LIN_Value: accessed-variable=VeDMIR_e_ESaveLEDOn_LIN.Value
              OUT_VeDMIR_e_PaddleModeSts_Value: accessed-variable=VeDMIR_e_PaddleModeSts.Value
              OUT_VeDMIR_y_eCoastingPopupMsg_Value: accessed-variable=VeDMIR_y_eCoastingPopupMsg.Value
              OUT_VeDMIR_e_BrakingMdReq_Value: accessed-variable=VeDMIR_e_BrakingMdReq.Value
              OUT_NeDMIR_e_eCoastLvlLatched_NeDMIR_e_eCoastLvlLatched: accessed-variable=NeDMIR_e_eCoastLvlLatched.NeDMIR_e_eCoastLvlLatched
              OUT_NeDMIR_e_eCoastDefaultAuto_NeDMIR_e_eCoastDefaultAuto: accessed-variable=NeDMIR_e_eCoastDefaultAuto.NeDMIR_e_eCoastDefaultAuto
              OUT_NeDMIR_e_eCoastDefaultCustom_NeDMIR_e_eCoastDefaultCustom: accessed-variable=NeDMIR_e_eCoastDefaultCustom.NeDMIR_e_eCoastDefaultCustom
        DMIR_PwrOn
          data-receive-point-by-arguments:
            11 x access:
              IN_EeDMIR_d_ChargeTypeCnf_Rx_EeDMIR_d_ChargeTypeCnf: accessed-variable=EeDMIR_d_ChargeTypeCnf_Rx.EeDMIR_d_ChargeTypeCnf
              IN_EeDMIR_d_TgtSOCRngCnf_Rx_EeDMIR_d_TgtSOCRngCnf: accessed-variable=EeDMIR_d_TgtSOCRngCnf_Rx.EeDMIR_d_TgtSOCRngCnf
              IN_NeDMIR_e_CreepSts_Rx_NeDMIR_e_CreepSts: accessed-variable=NeDMIR_e_CreepSts_Rx.NeDMIR_e_CreepSts
              IN_NeDMIR_e_DriveStyleSts_Rx_NeDMIR_e_DriveStyleSts: accessed-variable=NeDMIR_e_DriveStyleSts_Rx.NeDMIR_e_DriveStyleSts
              IN_NeDMIR_e_DrvMdArb_Rx_NeDMIR_e_DrvMdArb: accessed-variable=NeDMIR_e_DrvMdArb_Rx.NeDMIR_e_DrvMdArb
              IN_NeDMIR_e_PddlMdStatus_Rx_NeDMIR_e_PddlMdStatus: accessed-variable=NeDMIR_e_PddlMdStatus_Rx.NeDMIR_e_PddlMdStatus
              IN_NeDMIR_e_RaceModeSts_Rx_NeDMIR_e_RaceModeSts: accessed-variable=NeDMIR_e_RaceModeSts_Rx.NeDMIR_e_RaceModeSts
              IN_NeDMIR_e_RegenSts_Rx_NeDMIR_e_RegenSts: accessed-variable=NeDMIR_e_RegenSts_Rx.NeDMIR_e_RegenSts
              IN_NeDMIR_e_eCoastDefaultAuto_Rx_NeDMIR_e_eCoastDefaultAuto: accessed-variable=NeDMIR_e_eCoastDefaultAuto_Rx.NeDMIR_e_eCoastDefaultAuto
              IN_NeDMIR_e_eCoastDefaultCustom_Rx_NeDMIR_e_eCoastDefaultCustom: accessed-variable=NeDMIR_e_eCoastDefaultCustom_Rx.NeDMIR_e_eCoastDefaultCustom
              IN_NeDMIR_e_eCoastLvlLatched_Rx_NeDMIR_e_eCoastLvlLatched: accessed-variable=NeDMIR_e_eCoastLvlLatched_Rx.NeDMIR_e_eCoastLvlLatched
          data-send-points:
            59 x access:
              OUT_VeDMIR_e_DrvMdRaw_Value: accessed-variable=VeDMIR_e_DrvMdRaw.Value
              OUT_VeDMIR_b_LatchEV_Value: accessed-variable=VeDMIR_b_LatchEV.Value
              OUT_VeDMIR_e_HybridMdLEDOn_Value: accessed-variable=VeDMIR_e_HybridMdLEDOn.Value
              OUT_VeDMIR_e_ElectricPlusLEDOn_Value: accessed-variable=VeDMIR_e_ElectricPlusLEDOn.Value
              OUT_VeDMIR_e_ESaveLEDOn_Value: accessed-variable=VeDMIR_e_ESaveLEDOn.Value
              OUT_VeDMIR_e_SportMdLEDOn_Value: accessed-variable=VeDMIR_e_SportMdLEDOn.Value
              OUT_VeDMIR_b_InternalLightSts_Value: accessed-variable=VeDMIR_b_InternalLightSts.Value
              OUT_VeDMIR_Pct_PanelIntensity_Value: accessed-variable=VeDMIR_Pct_PanelIntensity.Value
              OUT_VeDMIR_e_DrvMdInfoSt_Value: accessed-variable=VeDMIR_e_DrvMdInfoSt.Value
              OUT_VeDMIR_d_TgtSOCRngCnf_Value: accessed-variable=VeDMIR_d_TgtSOCRngCnf.Value
              OUT_VeDMIR_e_EChargeType_Value: accessed-variable=VeDMIR_e_EChargeType.Value
              OUT_VeDMIR_e_SailOffStatus_Value: accessed-variable=VeDMIR_e_SailOffStatus.Value
              OUT_VeDMIR_e_SailOffStatus_Internal_Value: accessed-variable=VeDMIR_e_SailOffStatus_Internal.Value
              OUT_VeDMIR_b_DrvMdNotAvailDiag_Value: accessed-variable=VeDMIR_b_DrvMdNotAvailDiag.Value
              OUT_VeDMIR_b_CommFault_Value: accessed-variable=VeDMIR_b_CommFault.Value
              OUT_VeDMIR_b_CommFaultESave_Value: accessed-variable=VeDMIR_b_CommFaultESave.Value
              OUT_VeDMIR_Pct_HV_BatSOCTarget_Value: accessed-variable=VeDMIR_Pct_HV_BatSOCTarget.Value
              OUT_VeDMIR_b_ESaveBtnVolt1ShortToPwr_Value: accessed-variable=VeDMIR_b_ESaveBtnVolt1ShortToPwr.Value
              OUT_VeDMIR_b_ESaveBtnVolt1ShortToGrnd_Value: accessed-variable=VeDMIR_b_ESaveBtnVolt1ShortToGrnd.Value
              OUT_VeDMIR_b_ESaveBtnVoltDiffBtn_Value: accessed-variable=VeDMIR_b_ESaveBtnVoltDiffBtn.Value
              OUT_VeDMIR_b_HybridBtnVolt1ShortToPwr_Value: accessed-variable=VeDMIR_b_HybridBtnVolt1ShortToPwr.Value
              OUT_VeDMIR_b_HybridBtnVolt1ShortToGrnd_Value: accessed-variable=VeDMIR_b_HybridBtnVolt1ShortToGrnd.Value
              OUT_VeDMIR_b_HybridBtnVoltDiffBtn_Value: accessed-variable=VeDMIR_b_HybridBtnVoltDiffBtn.Value
              OUT_VeDMIR_b_EvBtnVolt1ShortToPwr_Value: accessed-variable=VeDMIR_b_EvBtnVolt1ShortToPwr.Value
              OUT_VeDMIR_b_EvBtnVolt1ShortToGrnd_Value: accessed-variable=VeDMIR_b_EvBtnVolt1ShortToGrnd.Value
              OUT_VeDMIR_b_EvBtnVoltDiffBtn_Value: accessed-variable=VeDMIR_b_EvBtnVoltDiffBtn.Value
              OUT_VeDMIR_b_DenyESave_TonaleDiag_Value: accessed-variable=VeDMIR_b_DenyESave_TonaleDiag.Value
              OUT_VeDMIR_b_ElectricPlusSwitchActv_Value: accessed-variable=VeDMIR_b_ElectricPlusSwitchActv.Value
              OUT_VeDMIR_b_ESaveMdBtnActv_Value: accessed-variable=VeDMIR_b_ESaveMdBtnActv.Value
              OUT_VeDMIR_b_HybridBtnActv_Value: accessed-variable=VeDMIR_b_HybridBtnActv.Value
              OUT_VeDMIR_b_DNA_ESaveStatus_Value: accessed-variable=VeDMIR_b_DNA_ESaveStatus.Value
              OUT_VeDMIR_e_eCoastingSts_Value: accessed-variable=VeDMIR_e_eCoastingSts.Value
              OUT_VeDMIR_e_TellTaleSts_Value: accessed-variable=VeDMIR_e_TellTaleSts.Value
              OUT_VeDMIR_e_TellTaleInfo_Value: accessed-variable=VeDMIR_e_TellTaleInfo.Value
              OUT_VeDMIR_e_eCoast_PopUpRqst_Value: accessed-variable=VeDMIR_e_eCoast_PopUpRqst.Value
              OUT_VeDMIR_e_eCoastingSel_Value: accessed-variable=VeDMIR_e_eCoastingSel.Value
              OUT_VeDMIR_b_eBoostRequest_Value: accessed-variable=VeDMIR_b_eBoostRequest.Value
              OUT_VeDMIR_b_eBoostSwitchFailSts_Value: accessed-variable=VeDMIR_b_eBoostSwitchFailSts.Value
              OUT_VeDMIR_e_DriveStyleSts_Value: accessed-variable=VeDMIR_e_DriveStyleSts.Value
              OUT_VeDMIR_b_DriveStyleStsFA_Value: accessed-variable=VeDMIR_b_DriveStyleStsFA.Value
              OUT_VeDMIR_e_EcoLEDOn_Value: accessed-variable=VeDMIR_e_EcoLEDOn.Value
              OUT_VeDMIR_e_RegenSts_Value: accessed-variable=VeDMIR_e_RegenSts.Value
              OUT_VeDMIR_e_FaultSts_DrvrModSelSwBCkt_Perf_Value: accessed-variable=VeDMIR_e_FaultSts_DrvrModSelSwBCkt_Perf.Value
              OUT_VeDMIR_e_FaultSts_DrvrModSelSwB_CktHi_Value: accessed-variable=VeDMIR_e_FaultSts_DrvrModSelSwB_CktHi.Value
              OUT_VeDMIR_e_FaultSts_DrvrModSelSwB_CktLo_Value: accessed-variable=VeDMIR_e_FaultSts_DrvrModSelSwB_CktLo.Value
              OUT_VeDMIR_e_FaultSts_DrvrModSelSwA_CktHi_Value: accessed-variable=VeDMIR_e_FaultSts_DrvrModSelSwA_CktHi.Value
              OUT_VeDMIR_e_FaultSts_DrvrModSelSwA_CktLo_Value: accessed-variable=VeDMIR_e_FaultSts_DrvrModSelSwA_CktLo.Value
              OUT_VeDMIR_e_FaultSts_DrvrModSelSwA_CktPerf_Value: accessed-variable=VeDMIR_e_FaultSts_DrvrModSelSwA_CktPerf.Value
              OUT_VeDMIR_e_FaultSts_EcoModSwHi_Value: accessed-variable=VeDMIR_e_FaultSts_EcoModSwHi.Value
              OUT_VeDMIR_e_FaultSts_EcoModSwLo_Value: accessed-variable=VeDMIR_e_FaultSts_EcoModSwLo.Value
              OUT_VeDMIR_e_FaultSts_EcoModSwPerf_Value: accessed-variable=VeDMIR_e_FaultSts_EcoModSwPerf.Value
              OUT_VeDMIR_e_CreepSts_Value: accessed-variable=VeDMIR_e_CreepSts.Value
              OUT_VeDMIR_e_EcoLEDOn_LIN_Value: accessed-variable=VeDMIR_e_EcoLEDOn_LIN.Value
              OUT_VeDMIR_e_ElectricPlusLEDOn_LIN_Value: accessed-variable=VeDMIR_e_ElectricPlusLEDOn_LIN.Value
              OUT_VeDMIR_e_ESaveLEDOn_LIN_Value: accessed-variable=VeDMIR_e_ESaveLEDOn_LIN.Value
              OUT_VeDMIR_e_PaddleModeSts_Value: accessed-variable=VeDMIR_e_PaddleModeSts.Value
              OUT_VeDMIR_y_eCoastingPopupMsg_Value: accessed-variable=VeDMIR_y_eCoastingPopupMsg.Value
              OUT_VeDMIR_b_eRuptRequest_Value: accessed-variable=VeDMIR_b_eRuptRequest.Value
              OUT_VeDMIR_e_BrakingMdReq_Value: accessed-variable=VeDMIR_e_BrakingMdReq.Value
          written-local-variables:
            70 x access:
              WV_Comm_Pct_HV_BatSOCTarget_write_IRV: accessed-variable=Comm_Pct_HV_BatSOCTarget_write_IRV
              WV_Comm_Pct_PanelIntensity_write_IRV: accessed-variable=Comm_Pct_PanelIntensity_write_IRV
              WV_Comm_DodgeSportSts_write_IRV: accessed-variable=Comm_DodgeSportSts_write_IRV
              WV_Comm_b_DriveStyleStsFA_write_IRV: accessed-variable=Comm_b_DriveStyleStsFA_write_IRV
              WV_Comm_b_DrvMdDrvrInputFA_write_IRV: accessed-variable=Comm_b_DrvMdDrvrInputFA_write_IRV
              WV_Comm_b_DrvMdReqErr_write_IRV: accessed-variable=Comm_b_DrvMdReqErr_write_IRV
              WV_Comm_b_ESaveBtnFA_write_IRV: accessed-variable=Comm_b_ESaveBtnFA_write_IRV
              WV_Comm_b_EVBtnFA_write_IRV: accessed-variable=Comm_b_EVBtnFA_write_IRV
              WV_Comm_EcoBtnStFA_write_IRV: accessed-variable=Comm_EcoBtnStFA_write_IRV
              WV_Comm_b_InternalLightSts_write_IRV: accessed-variable=Comm_b_InternalLightSts_write_IRV
              WV_Comm_PaddlesFailStsFA_write_IRV: accessed-variable=Comm_PaddlesFailStsFA_write_IRV
              WV_Comm_PaddlesFailSts_write_IRV: accessed-variable=Comm_PaddlesFailSts_write_IRV
              WV_Comm_PaddlesStsFA_write_IRV: accessed-variable=Comm_PaddlesStsFA_write_IRV
              WV_Comm_eDriveModeSwitchRqstFA_write_IRV: accessed-variable=Comm_eDriveModeSwitchRqstFA_write_IRV
              WV_Comm_e_DriveStyleSts_write_IRV: accessed-variable=Comm_e_DriveStyleSts_write_IRV
              WV_Comm_e_DrvMdDrvrInput_write_IRV: accessed-variable=Comm_e_DrvMdDrvrInput_write_IRV
              WV_Comm_e_EChargeType_write_IRV: accessed-variable=Comm_e_EChargeType_write_IRV
              WV_Comm_e_ESaveBtn_write_IRV: accessed-variable=Comm_e_ESaveBtn_write_IRV
              WV_Comm_EcoBtnSt_write_IRV: accessed-variable=Comm_EcoBtnSt_write_IRV
              WV_Comm_e_ElectricPlusSwitch_write_IRV: accessed-variable=Comm_e_ElectricPlusSwitch_write_IRV
              WV_Comm_e_KeDMIR_e_BrakingMdReq_write_IRV: accessed-variable=Comm_e_KeDMIR_e_BrakingMdReq_write_IRV
              WV_Comm_PaddlesSts_write_IRV: accessed-variable=Comm_PaddlesSts_write_IRV
              WV_Comm_eDriveModeSwitchRqst_write_IRV: accessed-variable=Comm_eDriveModeSwitchRqst_write_IRV
              WV_DenyEsave_TonaleDiag_write_IRV: accessed-variable=DenyEsave_TonaleDiag_write_IRV
              WV_DriveReady_write_IRV: accessed-variable=DriveReady_write_IRV
              WV_DrvMdArb_write_IRV: accessed-variable=DrvMdArb_write_IRV
              WV_ESaveModeDenied_write_IRV: accessed-variable=ESaveModeDenied_write_IRV
              WV_EVModeDenied_write_IRV: accessed-variable=EVModeDenied_write_IRV
              WV_EVModeInhibit2_write_IRV: accessed-variable=EVModeInhibit2_write_IRV
              WV_EcoDenied_write_IRV: accessed-variable=EcoDenied_write_IRV
              WV_EngOnEVFnlHMI_write_IRV: accessed-variable=EngOnEVFnlHMI_write_IRV
              WV_EngOnInEVLED_write_IRV: accessed-variable=EngOnInEVLED_write_IRV
              WV_EngOnWOTRsnFnl_write_IRV: accessed-variable=EngOnWOTRsnFnl_write_IRV
              WV_EngOnWOTRsnRaw_write_IRV: accessed-variable=EngOnWOTRsnRaw_write_IRV
              WV_HybridModeDenied_write_IRV: accessed-variable=HybridModeDenied_write_IRV
              WV_PowerMode_write_IRV: accessed-variable=PowerMode_write_IRV
              WV_SportModeDenied_write_IRV: accessed-variable=SportModeDenied_write_IRV
              WV_SailOff_Request_write_IRV: accessed-variable=SailOff_Request_write_IRV
              WV_VeDMDI_e_TgtSOCRngCnf_write_IRV: accessed-variable=VeDMDI_e_TgtSOCRngCnf_write_IRV
              WV_VeDMIC_Pct_PanelIntensity_write_IRV: accessed-variable=VeDMIC_Pct_PanelIntensity_write_IRV
              WV_VeDMIC_b_EcoLEDOn_write_IRV: accessed-variable=VeDMIC_b_EcoLEDOn_write_IRV
              WV_VeDMIC_b_InternalLightSts_write_IRV: accessed-variable=VeDMIC_b_InternalLightSts_write_IRV
              WV_VeDMIC_e_DrvMdInfoSt_write_IRV: accessed-variable=VeDMIC_e_DrvMdInfoSt_write_IRV
              WV_VeDMIC_e_DrvMdRaw_write_IRV: accessed-variable=VeDMIC_e_DrvMdRaw_write_IRV
              WV_VeDMIC_e_ESaveLEDOn_write_IRV: accessed-variable=VeDMIC_e_ESaveLEDOn_write_IRV
              WV_VeDMIC_e_EVMdLEDOn_write_IRV: accessed-variable=VeDMIC_e_EVMdLEDOn_write_IRV
              WV_VeDMIC_e_HybridMdLEDOn_write_IRV: accessed-variable=VeDMIC_e_HybridMdLEDOn_write_IRV
              WV_VeDMIC_e_SportLEDOn_write_IRV: accessed-variable=VeDMIC_e_SportLEDOn_write_IRV
              WV_VeDMID_b_DrvMdNotAvailDiag_write_IRV: accessed-variable=VeDMID_b_DrvMdNotAvailDiag_write_IRV
              WV_VeDMID_b_HybridBtnActv_write_IRV: accessed-variable=VeDMID_b_HybridBtnActv_write_IRV
              WV_VeDMIR_b_DrvMdReqErrFA_write_IRV: accessed-variable=VeDMIR_b_DrvMdReqErrFA_write_IRV
              WV_VeDMIR_b_DrvMdReqErr_write_IRV: accessed-variable=VeDMIR_b_DrvMdReqErr_write_IRV
              WV_VeDMIR_b_ESCOffActv_write_IRV: accessed-variable=VeDMIR_b_ESCOffActv_write_IRV
              WV_VeDMIR_b_InternalLightStsFA_write_IRV: accessed-variable=VeDMIR_b_InternalLightStsFA_write_IRV
              WV_VeDMIR_b_InternalLightSts_write_IRV: accessed-variable=VeDMIR_b_InternalLightSts_write_IRV
              WV_VeDMIR_b_PaddlesFailSts_write_IRV: accessed-variable=VeDMIR_b_PaddlesFailSts_write_IRV
              WV_VeDMIR_b_SailOff_Request_write_IRV: accessed-variable=VeDMIR_b_SailOff_Request_write_IRV
              WV_VeDMIR_e_CFGFeature_write_IRV: accessed-variable=VeDMIR_e_CFGFeature_write_IRV
              WV_VeDMIR_e_CFG_Set_write_IRV: accessed-variable=VeDMIR_e_CFG_Set_write_IRV
              WV_VeDMIR_e_ECoastingReq_IRV: accessed-variable=VeDMIR_e_ECoastingReq_IRV
              WV_VeDMIR_e_ESaveBtnStLIN_write_IRV: accessed-variable=VeDMIR_e_ESaveBtnStLIN_write_IRV
              WV_VeDMIR_e_EcoBtnStLIN_write_IRV: accessed-variable=VeDMIR_e_EcoBtnStLIN_write_IRV
              WV_VeDMIR_e_EcoBtnSt_write_IRV: accessed-variable=VeDMIR_e_EcoBtnSt_write_IRV
              WV_VeDMIR_e_ElectricPlusSwitchLIN_write_IRV: accessed-variable=VeDMIR_e_ElectricPlusSwitchLIN_write_IRV
              WV_VeDMIR_e_ElectricPlusSwitch_write_IRV: accessed-variable=VeDMIR_e_ElectricPlusSwitch_write_IRV
              WV_VeDMIR_e_PaddleSts_write_IRV: accessed-variable=VeDMIR_e_PaddleSts_write_IRV
              WV_VeDMIR_e_PddlMdReq_IRV: accessed-variable=VeDMIR_e_PddlMdReq_IRV
              WV_VeDMIR_e_PoweshotSts_IRV: accessed-variable=VeDMIR_e_PoweshotSts_IRV
              WV_VeDMIR_e_StReq_write_IRV: accessed-variable=VeDMIR_e_StReq_write_IRV
              WV_VeDMIR_e_eSaveSwitch_write_IRV: accessed-variable=VeDMIR_e_eSaveSwitch_write_IRV
        DMIR_MedTED1
          data-receive-point-by-arguments:
            64 x access:
              IN_VeAECR_e_AeCoastStat_Value: accessed-variable=VeAECR_e_AeCoastStat.Value
              IN_VeASLR_e_HDC_Status_Value: accessed-variable=VeASLR_e_HDC_Status.Value
              IN_VeBRKR_Pct_BrkTravelSts_Value: accessed-variable=VeBRKR_Pct_BrkTravelSts.Value
              IN_VeBRKR_b_AeCoastReady_Value: accessed-variable=VeBRKR_b_AeCoastReady.Value
              IN_VeBRKR_b_BrkPdlFlt_Value: accessed-variable=VeBRKR_b_BrkPdlFlt.Value
              IN_VeBRKR_b_ImpndSkid_Value: accessed-variable=VeBRKR_b_ImpndSkid.Value
              IN_VeCCTR_b_ACCTrqEnabled_BSM_Value: accessed-variable=VeCCTR_b_ACCTrqEnabled_BSM.Value
              IN_VeCCTR_b_CcEngaged_Value: accessed-variable=VeCCTR_b_CcEngaged.Value
              IN_VeCSVR_v_VehSpdSigned_Value: accessed-variable=VeCSVR_v_VehSpdSigned.Value
              IN_VeDFIR_b_IsDiagGlobalConditionsValid_Value: accessed-variable=VeDFIR_b_IsDiagGlobalConditionsValid.Value
              IN_VeDMAB_y_StatusByte_DrvrModSelSwA_CktHi_Value: accessed-variable=VeDMAB_y_StatusByte_DrvrModSelSwA_CktHi.Value
              IN_VeDMAB_y_StatusByte_DrvrModSelSwA_CktLo_Value: accessed-variable=VeDMAB_y_StatusByte_DrvrModSelSwA_CktLo.Value
              IN_VeDMAB_y_StatusByte_DrvrModSelSwA_CktPerf_Value: accessed-variable=VeDMAB_y_StatusByte_DrvrModSelSwA_CktPerf.Value
              IN_VeDMAB_y_StatusByte_DrvrModSelSwBCkt_Perf_Value: accessed-variable=VeDMAB_y_StatusByte_DrvrModSelSwBCkt_Perf.Value
              IN_VeDMAB_y_StatusByte_DrvrModSelSwB_CktHi_Value: accessed-variable=VeDMAB_y_StatusByte_DrvrModSelSwB_CktHi.Value
              IN_VeDMAB_y_StatusByte_DrvrModSelSwB_CktLo_Value: accessed-variable=VeDMAB_y_StatusByte_DrvrModSelSwB_CktLo.Value
              IN_VeDMAB_y_StatusByte_EcoModSwHi_Value: accessed-variable=VeDMAB_y_StatusByte_EcoModSwHi.Value
              IN_VeDMAB_y_StatusByte_EcoModSwLo_Value: accessed-variable=VeDMAB_y_StatusByte_EcoModSwLo.Value
              IN_VeDMAB_y_StatusByte_EcoModSwPerf_Value: accessed-variable=VeDMAB_y_StatusByte_EcoModSwPerf.Value
              IN_VeDMAB_y_StatusByte_InvData_BCM_Value: accessed-variable=VeDMAB_y_StatusByte_InvData_BCM.Value
              IN_VeDMAB_y_StatusByte_InvData_BECM_Value: accessed-variable=VeDMAB_y_StatusByte_InvData_BECM.Value
              IN_VeDMAB_y_StatusByte_InvData_ECM_Value: accessed-variable=VeDMAB_y_StatusByte_InvData_ECM.Value
              IN_VeDMAB_y_StatusByte_InvData_ECM_BusB_Value: accessed-variable=VeDMAB_y_StatusByte_InvData_ECM_BusB.Value
              IN_VeDMAB_y_StatusByte_InvData_ESBM_Value: accessed-variable=VeDMAB_y_StatusByte_InvData_ESBM.Value
              IN_VeDMAB_y_StatusByte_LosCommBECM_A_Value: accessed-variable=VeDMAB_y_StatusByte_LosCommBECM_A.Value
              IN_VeDMAB_y_StatusByte_LostCommBCM_Value: accessed-variable=VeDMAB_y_StatusByte_LostCommBCM.Value
              IN_VeDMAB_y_StatusByte_LostCommECM_A_BusB_Value: accessed-variable=VeDMAB_y_StatusByte_LostCommECM_A_BusB.Value
              IN_VeDMAB_y_StatusByte_LostCommECM_PCM_A_Value: accessed-variable=VeDMAB_y_StatusByte_LostCommECM_PCM_A.Value
              IN_VeDMAB_y_StatusByte_LostCommESBM_Value: accessed-variable=VeDMAB_y_StatusByte_LostCommESBM.Value
              IN_VeDMAB_y_StatusByte_LostCommRadio_Value: accessed-variable=VeDMAB_y_StatusByte_LostCommRadio.Value
              IN_VeDMDR_b_ESaveDenied_Value: accessed-variable=VeDMDR_b_ESaveDenied.Value
              IN_VeDMDR_b_EVDenied_Value: accessed-variable=VeDMDR_b_EVDenied.Value
              IN_VeDMDR_b_EcoDenied_Value: accessed-variable=VeDMDR_b_EcoDenied.Value
              IN_VeDMDR_b_EngOnEVHMI_Value: accessed-variable=VeDMDR_b_EngOnEVHMI.Value
              IN_VeDMDR_b_EngOnEVLED_Value: accessed-variable=VeDMDR_b_EngOnEVLED.Value
              IN_VeDMDR_b_EngOnWOTRsnFinal_Value: accessed-variable=VeDMDR_b_EngOnWOTRsnFinal.Value
              IN_VeDMDR_b_EngOnWOTRsnRaw_Value: accessed-variable=VeDMDR_b_EngOnWOTRsnRaw.Value
              IN_VeDMDR_b_HybridDenied_Value: accessed-variable=VeDMDR_b_HybridDenied.Value
              IN_VeDMDR_b_SportDenied_Value: accessed-variable=VeDMDR_b_SportDenied.Value
              IN_VeDMDR_d_ESaveActvDeniedRsn_Value: accessed-variable=VeDMDR_d_ESaveActvDeniedRsn.Value
              IN_VeDMDR_d_ESaveDeniedRsn_Value: accessed-variable=VeDMDR_d_ESaveDeniedRsn.Value
              IN_VeDMDR_d_EVDeniedRsn_Value: accessed-variable=VeDMDR_d_EVDeniedRsn.Value
              IN_VeDMDR_e_DrvMdArb_Value: accessed-variable=VeDMDR_e_DrvMdArb.Value
              IN_VeDMDR_e_DrvMdInt_Value: accessed-variable=VeDMDR_e_DrvMdInt.Value
              IN_VeDMDR_e_TurtleMdSts_Value: accessed-variable=VeDMDR_e_TurtleMdSts.Value
              IN_VeDMIB_e_PadLvrSts_Value: accessed-variable=VeDMIB_e_PadLvrSts.Value
              IN_VeDTRR_e_OPD_Sts_Value: accessed-variable=VeDTRR_e_OPD_Sts.Value
              IN_VeEBMR_e_eBoostStatus_Value: accessed-variable=VeEBMR_e_eBoostStatus.Value
              IN_VeHMIR_b_DriveReady_Value: accessed-variable=VeHMIR_b_DriveReady.Value
              IN_VePLTR_b_Hill_Des_Stat_Prx_Value: accessed-variable=VePLTR_b_Hill_Des_Stat_Prx.Value
              IN_VePLTR_e_ACCSystemSts_Value: accessed-variable=VePLTR_e_ACCSystemSts.Value
              IN_VePLTR_t_HCPOffTime_Value: accessed-variable=VePLTR_t_HCPOffTime.Value
              IN_VePMDR_e_PMM_PowerMode_Value: accessed-variable=VePMDR_e_PMM_PowerMode.Value
              IN_VeRGNR_b_AeCoast_Act_Value: accessed-variable=VeRGNR_b_AeCoast_Act.Value
              IN_VeRGNR_b_AeCoast_ActHCP_Value: accessed-variable=VeRGNR_b_AeCoast_ActHCP.Value
              IN_VeSTRR_g_EVModeInhbtRsn2_Value: accessed-variable=VeSTRR_g_EVModeInhbtRsn2.Value
              IN_VeTIMR_b_ModeSoftLatch_Value: accessed-variable=VeTIMR_b_ModeSoftLatch.Value
              IN_VeTIMR_e_RaceModeSts_Value: accessed-variable=VeTIMR_e_RaceModeSts.Value
              IN_VeTMDR_e_PropulsionMd_Value: accessed-variable=VeTMDR_e_PropulsionMd.Value
              IN_VeTRGR_b_ManualMode_Value: accessed-variable=VeTRGR_b_ManualMode.Value
              IN_VeTRGR_e_VldtdTransRngSt_Value: accessed-variable=VeTRGR_e_VldtdTransRngSt.Value
              IN_VeVSMR_e_VirtShftMd_Value: accessed-variable=VeVSMR_e_VirtShftMd.Value
              IN_VeVSMR_e_VirtShftMdPopUp_Value: accessed-variable=VeVSMR_e_VirtShftMdPopUp.Value
              IN_VeVTXR_e_PowerPanelMd_Value: accessed-variable=VeVTXR_e_PowerPanelMd.Value
          data-send-points:
            58 x access:
              OUT_VeDMIR_e_DrvMdRaw_Value: accessed-variable=VeDMIR_e_DrvMdRaw.Value
              OUT_VeDMIR_b_LatchEV_Value: accessed-variable=VeDMIR_b_LatchEV.Value
              OUT_VeDMIR_e_HybridMdLEDOn_Value: accessed-variable=VeDMIR_e_HybridMdLEDOn.Value
              OUT_VeDMIR_e_ElectricPlusLEDOn_Value: accessed-variable=VeDMIR_e_ElectricPlusLEDOn.Value
              OUT_VeDMIR_e_ESaveLEDOn_Value: accessed-variable=VeDMIR_e_ESaveLEDOn.Value
              OUT_VeDMIR_e_SportMdLEDOn_Value: accessed-variable=VeDMIR_e_SportMdLEDOn.Value
              OUT_VeDMIR_b_InternalLightSts_Value: accessed-variable=VeDMIR_b_InternalLightSts.Value
              OUT_VeDMIR_Pct_PanelIntensity_Value: accessed-variable=VeDMIR_Pct_PanelIntensity.Value
              OUT_VeDMIR_e_DrvMdInfoSt_Value: accessed-variable=VeDMIR_e_DrvMdInfoSt.Value
              OUT_VeDMIR_d_TgtSOCRngCnf_Value: accessed-variable=VeDMIR_d_TgtSOCRngCnf.Value
              OUT_VeDMIR_e_EChargeType_Value: accessed-variable=VeDMIR_e_EChargeType.Value
              OUT_VeDMIR_e_SailOffStatus_Value: accessed-variable=VeDMIR_e_SailOffStatus.Value
              OUT_VeDMIR_e_SailOffStatus_Internal_Value: accessed-variable=VeDMIR_e_SailOffStatus_Internal.Value
              OUT_VeDMIR_b_DrvMdNotAvailDiag_Value: accessed-variable=VeDMIR_b_DrvMdNotAvailDiag.Value
              OUT_VeDMIR_b_CommFault_Value: accessed-variable=VeDMIR_b_CommFault.Value
              OUT_VeDMIR_b_CommFaultESave_Value: accessed-variable=VeDMIR_b_CommFaultESave.Value
              OUT_VeDMIR_Pct_HV_BatSOCTarget_Value: accessed-variable=VeDMIR_Pct_HV_BatSOCTarget.Value
              OUT_VeDMIR_b_ESaveBtnVolt1ShortToPwr_Value: accessed-variable=VeDMIR_b_ESaveBtnVolt1ShortToPwr.Value
              OUT_VeDMIR_b_ESaveBtnVolt1ShortToGrnd_Value: accessed-variable=VeDMIR_b_ESaveBtnVolt1ShortToGrnd.Value
              OUT_VeDMIR_b_ESaveBtnVoltDiffBtn_Value: accessed-variable=VeDMIR_b_ESaveBtnVoltDiffBtn.Value
              OUT_VeDMIR_b_HybridBtnVolt1ShortToPwr_Value: accessed-variable=VeDMIR_b_HybridBtnVolt1ShortToPwr.Value
              OUT_VeDMIR_b_HybridBtnVolt1ShortToGrnd_Value: accessed-variable=VeDMIR_b_HybridBtnVolt1ShortToGrnd.Value
              OUT_VeDMIR_b_HybridBtnVoltDiffBtn_Value: accessed-variable=VeDMIR_b_HybridBtnVoltDiffBtn.Value
              OUT_VeDMIR_b_EvBtnVolt1ShortToPwr_Value: accessed-variable=VeDMIR_b_EvBtnVolt1ShortToPwr.Value
              OUT_VeDMIR_b_EvBtnVolt1ShortToGrnd_Value: accessed-variable=VeDMIR_b_EvBtnVolt1ShortToGrnd.Value
              OUT_VeDMIR_b_EvBtnVoltDiffBtn_Value: accessed-variable=VeDMIR_b_EvBtnVoltDiffBtn.Value
              OUT_VeDMIR_b_DenyESave_TonaleDiag_Value: accessed-variable=VeDMIR_b_DenyESave_TonaleDiag.Value
              OUT_VeDMIR_b_ElectricPlusSwitchActv_Value: accessed-variable=VeDMIR_b_ElectricPlusSwitchActv.Value
              OUT_VeDMIR_b_ESaveMdBtnActv_Value: accessed-variable=VeDMIR_b_ESaveMdBtnActv.Value
              OUT_VeDMIR_b_HybridBtnActv_Value: accessed-variable=VeDMIR_b_HybridBtnActv.Value
              OUT_VeDMIR_b_DNA_ESaveStatus_Value: accessed-variable=VeDMIR_b_DNA_ESaveStatus.Value
              OUT_VeDMIR_e_eCoastingSts_Value: accessed-variable=VeDMIR_e_eCoastingSts.Value
              OUT_VeDMIR_e_TellTaleSts_Value: accessed-variable=VeDMIR_e_TellTaleSts.Value
              OUT_VeDMIR_e_TellTaleInfo_Value: accessed-variable=VeDMIR_e_TellTaleInfo.Value
              OUT_VeDMIR_e_eCoast_PopUpRqst_Value: accessed-variable=VeDMIR_e_eCoast_PopUpRqst.Value
              OUT_VeDMIR_e_eCoastingSel_Value: accessed-variable=VeDMIR_e_eCoastingSel.Value
              OUT_VeDMIR_b_eBoostRequest_Value: accessed-variable=VeDMIR_b_eBoostRequest.Value
              OUT_VeDMIR_b_eBoostSwitchFailSts_Value: accessed-variable=VeDMIR_b_eBoostSwitchFailSts.Value
              OUT_VeDMIR_e_DriveStyleSts_Value: accessed-variable=VeDMIR_e_DriveStyleSts.Value
              OUT_VeDMIR_b_DriveStyleStsFA_Value: accessed-variable=VeDMIR_b_DriveStyleStsFA.Value
              OUT_VeDMIR_e_EcoLEDOn_Value: accessed-variable=VeDMIR_e_EcoLEDOn.Value
              OUT_VeDMIR_e_RegenSts_Value: accessed-variable=VeDMIR_e_RegenSts.Value
              OUT_VeDMIR_e_FaultSts_DrvrModSelSwBCkt_Perf_Value: accessed-variable=VeDMIR_e_FaultSts_DrvrModSelSwBCkt_Perf.Value
              OUT_VeDMIR_e_FaultSts_DrvrModSelSwB_CktHi_Value: accessed-variable=VeDMIR_e_FaultSts_DrvrModSelSwB_CktHi.Value
              OUT_VeDMIR_e_FaultSts_DrvrModSelSwB_CktLo_Value: accessed-variable=VeDMIR_e_FaultSts_DrvrModSelSwB_CktLo.Value
              OUT_VeDMIR_e_FaultSts_DrvrModSelSwA_CktHi_Value: accessed-variable=VeDMIR_e_FaultSts_DrvrModSelSwA_CktHi.Value
              OUT_VeDMIR_e_FaultSts_DrvrModSelSwA_CktLo_Value: accessed-variable=VeDMIR_e_FaultSts_DrvrModSelSwA_CktLo.Value
              OUT_VeDMIR_e_FaultSts_DrvrModSelSwA_CktPerf_Value: accessed-variable=VeDMIR_e_FaultSts_DrvrModSelSwA_CktPerf.Value
              OUT_VeDMIR_e_FaultSts_EcoModSwHi_Value: accessed-variable=VeDMIR_e_FaultSts_EcoModSwHi.Value
              OUT_VeDMIR_e_FaultSts_EcoModSwLo_Value: accessed-variable=VeDMIR_e_FaultSts_EcoModSwLo.Value
              OUT_VeDMIR_e_FaultSts_EcoModSwPerf_Value: accessed-variable=VeDMIR_e_FaultSts_EcoModSwPerf.Value
              OUT_VeDMIR_e_EcoLEDOn_LIN_Value: accessed-variable=VeDMIR_e_EcoLEDOn_LIN.Value
              OUT_VeDMIR_e_ElectricPlusLEDOn_LIN_Value: accessed-variable=VeDMIR_e_ElectricPlusLEDOn_LIN.Value
              OUT_VeDMIR_e_ESaveLEDOn_LIN_Value: accessed-variable=VeDMIR_e_ESaveLEDOn_LIN.Value
              OUT_VeDMIR_e_PaddleModeSts_Value: accessed-variable=VeDMIR_e_PaddleModeSts.Value
              OUT_VeDMIR_y_eCoastingPopupMsg_Value: accessed-variable=VeDMIR_y_eCoastingPopupMsg.Value
              OUT_VeDMIR_b_eRuptRequest_Value: accessed-variable=VeDMIR_b_eRuptRequest.Value
              OUT_VeDMIR_e_BrakingMdReq_Value: accessed-variable=VeDMIR_e_BrakingMdReq.Value
          read-local-variables:
            71 x access:
              RV_Comm_DodgeSportSts_write_IRV: accessed-variable=Comm_DodgeSportSts_write_IRV
              RV_Comm_EcoBtnStFA_write_IRV: accessed-variable=Comm_EcoBtnStFA_write_IRV
              RV_Comm_EcoBtnSt_write_IRV: accessed-variable=Comm_EcoBtnSt_write_IRV
              RV_Comm_PaddlesFailStsFA_write_IRV: accessed-variable=Comm_PaddlesFailStsFA_write_IRV
              RV_Comm_PaddlesFailSts_write_IRV: accessed-variable=Comm_PaddlesFailSts_write_IRV
              RV_Comm_PaddlesStsFA_write_IRV: accessed-variable=Comm_PaddlesStsFA_write_IRV
              RV_Comm_PaddlesSts_write_IRV: accessed-variable=Comm_PaddlesSts_write_IRV
              RV_Comm_Pct_HV_BatSOCTarget_write_IRV: accessed-variable=Comm_Pct_HV_BatSOCTarget_write_IRV
              RV_Comm_b_DriveStyleStsFA_write_IRV: accessed-variable=Comm_b_DriveStyleStsFA_write_IRV
              RV_Comm_b_DrvMdDrvrInputFA_write_IRV: accessed-variable=Comm_b_DrvMdDrvrInputFA_write_IRV
              RV_Comm_b_DrvMdReqErr_write_IRV: accessed-variable=Comm_b_DrvMdReqErr_write_IRV
              RV_Comm_b_ESaveBtnFA_write_IRV: accessed-variable=Comm_b_ESaveBtnFA_write_IRV
              RV_Comm_b_EVBtnFA_write_IRV: accessed-variable=Comm_b_EVBtnFA_write_IRV
              RV_Comm_eDriveModeSwitchRqstFA_write_IRV: accessed-variable=Comm_eDriveModeSwitchRqstFA_write_IRV
              RV_Comm_eDriveModeSwitchRqst_write_IRV: accessed-variable=Comm_eDriveModeSwitchRqst_write_IRV
              RV_Comm_e_DrvMdDrvrInput_write_IRV: accessed-variable=Comm_e_DrvMdDrvrInput_write_IRV
              RV_Comm_e_EChargeType_write_IRV: accessed-variable=Comm_e_EChargeType_write_IRV
              RV_Comm_e_ESaveBtn_write_IRV: accessed-variable=Comm_e_ESaveBtn_write_IRV
              RV_Comm_e_ElectricPlusSwitch_write_IRV: accessed-variable=Comm_e_ElectricPlusSwitch_write_IRV
              RV_Comm_e_KeDMIR_e_BrakingMdReq_write_IRV: accessed-variable=Comm_e_KeDMIR_e_BrakingMdReq_write_IRV
              RV_SailOff_Request_write_IRV: accessed-variable=SailOff_Request_write_IRV
              RV_VeDMDI_e_TgtSOCRngCnf_write_IRV: accessed-variable=VeDMDI_e_TgtSOCRngCnf_write_IRV
              RV_VeDMIC_Pct_PanelIntensity_write_IRV: accessed-variable=VeDMIC_Pct_PanelIntensity_write_IRV
              RV_VeDMIC_b_EcoLEDOn_write_IRV: accessed-variable=VeDMIC_b_EcoLEDOn_write_IRV
              RV_VeDMIC_b_InternalLightSts_write_IRV: accessed-variable=VeDMIC_b_InternalLightSts_write_IRV
              RV_VeDMIC_e_DrvMdInfoSt_write_IRV: accessed-variable=VeDMIC_e_DrvMdInfoSt_write_IRV
              RV_VeDMIC_e_ESaveLEDOn_write_IRV: accessed-variable=VeDMIC_e_ESaveLEDOn_write_IRV
              RV_VeDMIC_e_EVMdLEDOn_write_IRV: accessed-variable=VeDMIC_e_EVMdLEDOn_write_IRV
              RV_VeDMIC_e_HybridMdLEDOn_write_IRV: accessed-variable=VeDMIC_e_HybridMdLEDOn_write_IRV
              RV_VeDMIC_e_SportLEDOn_write_IRV: accessed-variable=VeDMIC_e_SportLEDOn_write_IRV
              RV_VeDMIR_Pct_HV_BatSOCTarget_GGGC_write_IRV: accessed-variable=VeDMIR_Pct_HV_BatSOCTarget_GGGC_write_IRV
              RV_VeDMIR_Pct_HV_BatSOCTarget_write_IRV: accessed-variable=VeDMIR_Pct_HV_BatSOCTarget_write_IRV
              RV_VeDMIR_Pct_PanelIntensity_write_IRV: accessed-variable=VeDMIR_Pct_PanelIntensity_write_IRV
              RV_VeDMIR_b_DriveStyleStsFA_write_IRV: accessed-variable=VeDMIR_b_DriveStyleStsFA_write_IRV
              RV_VeDMIR_b_DrvMdDrvrInputFA_write_IRV: accessed-variable=VeDMIR_b_DrvMdDrvrInputFA_write_IRV
              RV_VeDMIR_b_DrvMdReqErr_write_IRV: accessed-variable=VeDMIR_b_DrvMdReqErr_write_IRV
              RV_VeDMIR_b_EChargetypeFA_write_IRV: accessed-variable=VeDMIR_b_EChargetypeFA_write_IRV
              RV_VeDMIR_b_EChargetypeGGGCFA_write_IRV: accessed-variable=VeDMIR_b_EChargetypeGGGCFA_write_IRV
              RV_VeDMIR_b_ESCOffActv_write_IRV: accessed-variable=VeDMIR_b_ESCOffActv_write_IRV
              RV_VeDMIR_b_ESaveBtnStFA_write_IRV: accessed-variable=VeDMIR_b_ESaveBtnStFA_write_IRV
              RV_VeDMIR_b_ESaveBtnSt_CANFA_write_IRV: accessed-variable=VeDMIR_b_ESaveBtnSt_CANFA_write_IRV
              RV_VeDMIR_b_EVBtnStFA_write_IRV: accessed-variable=VeDMIR_b_EVBtnStFA_write_IRV
              RV_VeDMIR_b_EcoBtnStFA_write_IRV: accessed-variable=VeDMIR_b_EcoBtnStFA_write_IRV
              RV_VeDMIR_b_EcoBtnStLINFA_write_IRV: accessed-variable=VeDMIR_b_EcoBtnStLINFA_write_IRV
              RV_VeDMIR_b_ElectricPlusSwitchLINFA_write_IRV: accessed-variable=VeDMIR_b_ElectricPlusSwitchLINFA_write_IRV
              RV_VeDMIR_b_HV_BatSOCTargetFA_write_IRV: accessed-variable=VeDMIR_b_HV_BatSOCTargetFA_write_IRV
              RV_VeDMIR_b_HV_BatSOCTarget_GGGCFA_write_IRV: accessed-variable=VeDMIR_b_HV_BatSOCTarget_GGGCFA_write_IRV
              RV_VeDMIR_b_InternalLightSts_write_IRV: accessed-variable=VeDMIR_b_InternalLightSts_write_IRV
              RV_VeDMIR_b_PaddlesFailStsFA_write_IRV: accessed-variable=VeDMIR_b_PaddlesFailStsFA_write_IRV
              RV_VeDMIR_b_PaddlesFailSts_write_IRV: accessed-variable=VeDMIR_b_PaddlesFailSts_write_IRV
              RV_VeDMIR_b_PaddlesStsFA_write_IRV: accessed-variable=VeDMIR_b_PaddlesStsFA_write_IRV
              RV_VeDMIR_b_SailOff_Request_write_IRV: accessed-variable=VeDMIR_b_SailOff_Request_write_IRV
              RV_VeDMIR_b_SportStatus_write_IRV: accessed-variable=VeDMIR_b_SportStatus_write_IRV
              RV_VeDMIR_b_eDriveModeSwitchRqstFA_write_IRV: accessed-variable=VeDMIR_b_eDriveModeSwitchRqstFA_write_IRV
              RV_VeDMIR_e_CFGFeature_write_IRV: accessed-variable=VeDMIR_e_CFGFeature_write_IRV
              RV_VeDMIR_e_CFG_Set_write_IRV: accessed-variable=VeDMIR_e_CFG_Set_write_IRV
              RV_VeDMIR_e_DrvMdDrvrInput_write_IRV: accessed-variable=VeDMIR_e_DrvMdDrvrInput_write_IRV
              RV_VeDMIR_e_EChargetypeGGGC_write_IRV: accessed-variable=VeDMIR_e_EChargetypeGGGC_write_IRV
              RV_VeDMIR_e_EChargetype_write_IRV: accessed-variable=VeDMIR_e_EChargetype_write_IRV
              RV_VeDMIR_e_ECoastingReq_IRV: accessed-variable=VeDMIR_e_ECoastingReq_IRV
              RV_VeDMIR_e_ESaveBtnStLIN_write_IRV: accessed-variable=VeDMIR_e_ESaveBtnStLIN_write_IRV
              RV_VeDMIR_e_EcoBtnStLIN_write_IRV: accessed-variable=VeDMIR_e_EcoBtnStLIN_write_IRV
              RV_VeDMIR_e_EcoBtnSt_write_IRV: accessed-variable=VeDMIR_e_EcoBtnSt_write_IRV
              RV_VeDMIR_e_ElectricPlusSwitchLIN_write_IRV: accessed-variable=VeDMIR_e_ElectricPlusSwitchLIN_write_IRV
              RV_VeDMIR_e_ElectricPlusSwitch_write_IRV: accessed-variable=VeDMIR_e_ElectricPlusSwitch_write_IRV
              RV_VeDMIR_e_PaddleSts_write_IRV: accessed-variable=VeDMIR_e_PaddleSts_write_IRV
              RV_VeDMIR_e_PddlMdReq_IRV: accessed-variable=VeDMIR_e_PddlMdReq_IRV
              RV_VeDMIR_e_PoweshotSts_IRV: accessed-variable=VeDMIR_e_PoweshotSts_IRV
              RV_VeDMIR_e_StReq_write_IRV: accessed-variable=VeDMIR_e_StReq_write_IRV
              RV_VeDMIR_e_eDriveModeSwitchRqst_write_IRV: accessed-variable=VeDMIR_e_eDriveModeSwitchRqst_write_IRV
              RV_VeDMIR_e_eSaveSwitch_write_IRV: accessed-variable=VeDMIR_e_eSaveSwitch_write_IRV
          written-local-variables:
            41 x access:
              WV_Comm_DodgeSportSts_write_IRV: accessed-variable=Comm_DodgeSportSts_write_IRV
              WV_Comm_EcoBtnStFA_write_IRV: accessed-variable=Comm_EcoBtnStFA_write_IRV
              WV_Comm_EcoBtnSt_write_IRV: accessed-variable=Comm_EcoBtnSt_write_IRV
              WV_Comm_PaddlesFailStsFA_write_IRV: accessed-variable=Comm_PaddlesFailStsFA_write_IRV
              WV_Comm_PaddlesFailSts_write_IRV: accessed-variable=Comm_PaddlesFailSts_write_IRV
              WV_Comm_PaddlesStsFA_write_IRV: accessed-variable=Comm_PaddlesStsFA_write_IRV
              WV_Comm_PaddlesSts_write_IRV: accessed-variable=Comm_PaddlesSts_write_IRV
              WV_Comm_Pct_HV_BatSOCTarget_write_IRV: accessed-variable=Comm_Pct_HV_BatSOCTarget_write_IRV
              WV_Comm_Pct_PanelIntensity_write_IRV: accessed-variable=Comm_Pct_PanelIntensity_write_IRV
              WV_Comm_b_DriveStyleStsFA_write_IRV: accessed-variable=Comm_b_DriveStyleStsFA_write_IRV
              WV_Comm_b_DrvMdDrvrInputFA_write_IRV: accessed-variable=Comm_b_DrvMdDrvrInputFA_write_IRV
              WV_Comm_b_DrvMdReqErr_write_IRV: accessed-variable=Comm_b_DrvMdReqErr_write_IRV
              WV_Comm_b_ESaveBtnFA_write_IRV: accessed-variable=Comm_b_ESaveBtnFA_write_IRV
              WV_Comm_b_EVBtnFA_write_IRV: accessed-variable=Comm_b_EVBtnFA_write_IRV
              WV_Comm_b_InternalLightSts_write_IRV: accessed-variable=Comm_b_InternalLightSts_write_IRV
              WV_Comm_eDriveModeSwitchRqstFA_write_IRV: accessed-variable=Comm_eDriveModeSwitchRqstFA_write_IRV
              WV_Comm_eDriveModeSwitchRqst_write_IRV: accessed-variable=Comm_eDriveModeSwitchRqst_write_IRV
              WV_Comm_e_DriveStyleSts_write_IRV: accessed-variable=Comm_e_DriveStyleSts_write_IRV
              WV_Comm_e_DrvMdDrvrInput_write_IRV: accessed-variable=Comm_e_DrvMdDrvrInput_write_IRV
              WV_Comm_e_EChargeType_write_IRV: accessed-variable=Comm_e_EChargeType_write_IRV
              WV_Comm_e_ESaveBtn_write_IRV: accessed-variable=Comm_e_ESaveBtn_write_IRV
              WV_Comm_e_ElectricPlusSwitch_write_IRV: accessed-variable=Comm_e_ElectricPlusSwitch_write_IRV
              WV_DenyEsave_TonaleDiag_write_IRV: accessed-variable=DenyEsave_TonaleDiag_write_IRV
              WV_DriveReady_write_IRV: accessed-variable=DriveReady_write_IRV
              WV_DrvMdArb_write_IRV: accessed-variable=DrvMdArb_write_IRV
              WV_ESaveModeDenied_write_IRV: accessed-variable=ESaveModeDenied_write_IRV
              WV_EVModeDenied_write_IRV: accessed-variable=EVModeDenied_write_IRV
              WV_EVModeInhibit2_write_IRV: accessed-variable=EVModeInhibit2_write_IRV
              WV_EcoDenied_write_IRV: accessed-variable=EcoDenied_write_IRV
              WV_EngOnEVFnlHMI_write_IRV: accessed-variable=EngOnEVFnlHMI_write_IRV
              WV_EngOnInEVLED_write_IRV: accessed-variable=EngOnInEVLED_write_IRV
              WV_EngOnWOTRsnFnl_write_IRV: accessed-variable=EngOnWOTRsnFnl_write_IRV
              WV_EngOnWOTRsnRaw_write_IRV: accessed-variable=EngOnWOTRsnRaw_write_IRV
              WV_HybridModeDenied_write_IRV: accessed-variable=HybridModeDenied_write_IRV
              WV_PowerMode_write_IRV: accessed-variable=PowerMode_write_IRV
              WV_SailOff_Request_write_IRV: accessed-variable=SailOff_Request_write_IRV
              WV_SportModeDenied_write_IRV: accessed-variable=SportModeDenied_write_IRV
              WV_VeDMDI_e_TgtSOCRngCnf_write_IRV: accessed-variable=VeDMDI_e_TgtSOCRngCnf_write_IRV
              WV_VeDMIC_e_DrvMdRaw_write_IRV: accessed-variable=VeDMIC_e_DrvMdRaw_write_IRV
              WV_VeDMID_b_DrvMdNotAvailDiag_write_IRV: accessed-variable=VeDMID_b_DrvMdNotAvailDiag_write_IRV
              WV_VeDMID_b_HybridBtnActv_write_IRV: accessed-variable=VeDMID_b_HybridBtnActv_write_IRV
        DMIR_MedTED2
          data-receive-point-by-arguments:
            access IN_VeDMDR_d_EcoDeniedRsn_Value: accessed-variable=VeDMDR_d_EcoDeniedRsn.Value
          read-local-variables:
            21 x access:
              RV_Comm_Pct_PanelIntensity_write_IRV: accessed-variable=Comm_Pct_PanelIntensity_write_IRV
              RV_Comm_b_InternalLightSts_write_IRV: accessed-variable=Comm_b_InternalLightSts_write_IRV
              RV_Comm_e_DrvMdDrvrInput_write_IRV: accessed-variable=Comm_e_DrvMdDrvrInput_write_IRV
              RV_Comm_e_EChargeType_write_IRV: accessed-variable=Comm_e_EChargeType_write_IRV
              RV_DenyEsave_TonaleDiag_write_IRV: accessed-variable=DenyEsave_TonaleDiag_write_IRV
              RV_DriveReady_write_IRV: accessed-variable=DriveReady_write_IRV
              RV_DrvMdArb_write_IRV: accessed-variable=DrvMdArb_write_IRV
              RV_ESaveModeDenied_write_IRV: accessed-variable=ESaveModeDenied_write_IRV
              RV_EVModeDenied_write_IRV: accessed-variable=EVModeDenied_write_IRV
              RV_EVModeInhibit2_write_IRV: accessed-variable=EVModeInhibit2_write_IRV
              RV_EcoDenied_write_IRV: accessed-variable=EcoDenied_write_IRV
              RV_EngOnEVFnlHMI_write_IRV: accessed-variable=EngOnEVFnlHMI_write_IRV
              RV_EngOnInEVLED_write_IRV: accessed-variable=EngOnInEVLED_write_IRV
              RV_EngOnWOTRsnFnl_write_IRV: accessed-variable=EngOnWOTRsnFnl_write_IRV
              RV_EngOnWOTRsnRaw_write_IRV: accessed-variable=EngOnWOTRsnRaw_write_IRV
              RV_HybridModeDenied_write_IRV: accessed-variable=HybridModeDenied_write_IRV
              RV_PowerMode_write_IRV: accessed-variable=PowerMode_write_IRV
              RV_SportModeDenied_write_IRV: accessed-variable=SportModeDenied_write_IRV
              RV_VeDMIC_e_DrvMdRaw_write_IRV: accessed-variable=VeDMIC_e_DrvMdRaw_write_IRV
              RV_VeDMID_b_DrvMdNotAvailDiag_write_IRV: accessed-variable=VeDMID_b_DrvMdNotAvailDiag_write_IRV
              RV_VeDMID_b_HybridBtnActv_write_IRV: accessed-variable=VeDMID_b_HybridBtnActv_write_IRV
          written-local-variables:
            8 x access:
              WV_VeDMIC_Pct_PanelIntensity_write_IRV: accessed-variable=VeDMIC_Pct_PanelIntensity_write_IRV
              WV_VeDMIC_b_EcoLEDOn_write_IRV: accessed-variable=VeDMIC_b_EcoLEDOn_write_IRV
              WV_VeDMIC_b_InternalLightSts_write_IRV: accessed-variable=VeDMIC_b_InternalLightSts_write_IRV
              WV_VeDMIC_e_DrvMdInfoSt_write_IRV: accessed-variable=VeDMIC_e_DrvMdInfoSt_write_IRV
              WV_VeDMIC_e_ESaveLEDOn_write_IRV: accessed-variable=VeDMIC_e_ESaveLEDOn_write_IRV
              WV_VeDMIC_e_EVMdLEDOn_write_IRV: accessed-variable=VeDMIC_e_EVMdLEDOn_write_IRV
              WV_VeDMIC_e_HybridMdLEDOn_write_IRV: accessed-variable=VeDMIC_e_HybridMdLEDOn_write_IRV
              WV_VeDMIC_e_SportLEDOn_write_IRV: accessed-variable=VeDMIC_e_SportLEDOn_write_IRV
        DMIR_PwrOff
          data-send-points:
            11 x access:
              OUT_NeDMIR_e_eCoastLvlLatched_NeDMIR_e_eCoastLvlLatched: accessed-variable=NeDMIR_e_eCoastLvlLatched.NeDMIR_e_eCoastLvlLatched
              OUT_EeDMIR_d_ChargeTypeCnf_EeDMIR_d_ChargeTypeCnf: accessed-variable=EeDMIR_d_ChargeTypeCnf.EeDMIR_d_ChargeTypeCnf
              OUT_EeDMIR_d_TgtSOCRngCnf_EeDMIR_d_TgtSOCRngCnf: accessed-variable=EeDMIR_d_TgtSOCRngCnf.EeDMIR_d_TgtSOCRngCnf
              OUT_NeDMIR_e_DrvMdArb_NeDMIR_e_DrvMdArb: accessed-variable=NeDMIR_e_DrvMdArb.NeDMIR_e_DrvMdArb
              OUT_NeDMIR_e_DriveStyleSts_NeDMIR_e_DriveStyleSts: accessed-variable=NeDMIR_e_DriveStyleSts.NeDMIR_e_DriveStyleSts
              OUT_NeDMIR_e_RegenSts_NeDMIR_e_RegenSts: accessed-variable=NeDMIR_e_RegenSts.NeDMIR_e_RegenSts
              OUT_NeDMIR_e_eCoastDefaultAuto_NeDMIR_e_eCoastDefaultAuto: accessed-variable=NeDMIR_e_eCoastDefaultAuto.NeDMIR_e_eCoastDefaultAuto
              OUT_NeDMIR_e_eCoastDefaultCustom_NeDMIR_e_eCoastDefaultCustom: accessed-variable=NeDMIR_e_eCoastDefaultCustom.NeDMIR_e_eCoastDefaultCustom
              OUT_NeDMIR_e_CreepSts_NeDMIR_e_CreepSts: accessed-variable=NeDMIR_e_CreepSts.NeDMIR_e_CreepSts
              OUT_NeDMIR_e_RaceModeSts_NeDMIR_e_RaceModeSts: accessed-variable=NeDMIR_e_RaceModeSts.NeDMIR_e_RaceModeSts
              OUT_NeDMIR_e_PddlMdStatus_NeDMIR_e_PddlMdStatus: accessed-variable=NeDMIR_e_PddlMdStatus.NeDMIR_e_PddlMdStatus
        FsftDMIR_Pct_HV_BatSOCTarget
          written-local-variables:
            access WV_VeDMIR_Pct_HV_BatSOCTarget_write_IRV: accessed-variable=VeDMIR_Pct_HV_BatSOCTarget_write_IRV
            access WV_VeDMIR_b_HV_BatSOCTargetFA_write_IRV: accessed-variable=VeDMIR_b_HV_BatSOCTargetFA_write_IRV
        FsftDMIR_Pct_HV_BatSOCTarget_GGGC
          written-local-variables:
            access WV_VeDMIR_Pct_HV_BatSOCTarget_GGGC_write_IRV: accessed-variable=VeDMIR_Pct_HV_BatSOCTarget_GGGC_write_IRV
            access WV_VeDMIR_b_HV_BatSOCTarget_GGGCFA_write_IRV: accessed-variable=VeDMIR_b_HV_BatSOCTarget_GGGCFA_write_IRV
        FsftDMIR_Pct_PanelIntensity
          written-local-variables:
            access WV_VeDMIR_Pct_PanelIntensity_write_IRV: accessed-variable=VeDMIR_Pct_PanelIntensity_write_IRV
            access WV_VeDMIR_b_PanelIntensityFA_write_IRV: accessed-variable=VeDMIR_b_PanelIntensityFA_write_IRV
        FsftDMIR_b_DrvMdReqErr
          written-local-variables:
            access WV_VeDMIR_b_DrvMdReqErrFA_write_IRV: accessed-variable=VeDMIR_b_DrvMdReqErrFA_write_IRV
        FsftDMIR_b_EcoBtnSt
          written-local-variables:
            access WV_VeDMIR_b_EcoBtnStFA_write_IRV: accessed-variable=VeDMIR_b_EcoBtnStFA_write_IRV
        FsftDMIR_b_EcoBtnStLIN
          written-local-variables:
            access WV_VeDMIR_b_EcoBtnStLINFA_write_IRV: accessed-variable=VeDMIR_b_EcoBtnStLINFA_write_IRV
        FsftDMIR_b_ElectricPlusSwitchLIN
          written-local-variables:
            access WV_VeDMIR_b_ElectricPlusSwitchLINFA_write_IRV: accessed-variable=VeDMIR_b_ElectricPlusSwitchLINFA_write_IRV
        FsftDMIR_b_InternalLightSts
          written-local-variables:
            access WV_VeDMIR_b_InternalLightStsFA_write_IRV: accessed-variable=VeDMIR_b_InternalLightStsFA_write_IRV
        FsftDMIR_b_PaddlesFailSts
          written-local-variables:
            access WV_VeDMIR_b_PaddlesFailStsFA_write_IRV: accessed-variable=VeDMIR_b_PaddlesFailStsFA_write_IRV
        FsftDMIR_b_PaddlesSts
          written-local-variables:
            access WV_VeDMIR_b_PaddlesStsFA_write_IRV: accessed-variable=VeDMIR_b_PaddlesStsFA_write_IRV
        FsftDMIR_b_SportStatus
          written-local-variables:
            access WV_VeDMIR_b_SportStatus_write_IRV: accessed-variable=VeDMIR_b_SportStatus_write_IRV
        FsftDMIR_b_eDriveModeSwitchRqst
          written-local-variables:
            access WV_VeDMIR_b_eDriveModeSwitchRqstFA_write_IRV: accessed-variable=VeDMIR_b_eDriveModeSwitchRqstFA_write_IRV
            access WV_VeDMIR_e_eDriveModeSwitchRqst_write_IRV: accessed-variable=VeDMIR_e_eDriveModeSwitchRqst_write_IRV
        FsftDMIR_e_Braking_Mode_Req
        FsftDMIR_e_DriveStyleSts
          written-local-variables:
            access WV_VeDMIR_b_DriveStyleStsFA_write_IRV: accessed-variable=VeDMIR_b_DriveStyleStsFA_write_IRV
        FsftDMIR_e_DrvMdDrvrInput
          written-local-variables:
            access WV_VeDMIR_b_DrvMdDrvrInputFA_write_IRV: accessed-variable=VeDMIR_b_DrvMdDrvrInputFA_write_IRV
            access WV_VeDMIR_e_DrvMdDrvrInput_write_IRV: accessed-variable=VeDMIR_e_DrvMdDrvrInput_write_IRV
        FsftDMIR_e_EChargetype
          written-local-variables:
            access WV_VeDMIR_b_EChargetypeFA_write_IRV: accessed-variable=VeDMIR_b_EChargetypeFA_write_IRV
            access WV_VeDMIR_e_EChargetype_write_IRV: accessed-variable=VeDMIR_e_EChargetype_write_IRV
        FsftDMIR_e_EChargetype_GGGC
          written-local-variables:
            access WV_VeDMIR_b_EChargetypeGGGCFA_write_IRV: accessed-variable=VeDMIR_b_EChargetypeGGGCFA_write_IRV
            access WV_VeDMIR_e_EChargetypeGGGC_write_IRV: accessed-variable=VeDMIR_e_EChargetypeGGGC_write_IRV
        FsftDMIR_e_ESaveBtnSt
          written-local-variables:
            access WV_VeDMIR_b_ESaveBtnStFA_write_IRV: accessed-variable=VeDMIR_b_ESaveBtnStFA_write_IRV
        FsftDMIR_e_ESaveBtnSt_CAN
          written-local-variables:
            access WV_VeDMIR_b_ESaveBtnSt_CANFA_write_IRV: accessed-variable=VeDMIR_b_ESaveBtnSt_CANFA_write_IRV
        FsftDMIR_e_EVBtnSt
          written-local-variables:
            access WV_VeDMIR_b_EVBtnStFA_write_IRV: accessed-variable=VeDMIR_b_EVBtnStFA_write_IRV
        PokeDMIR_Pct_HV_BatSOCTarget
          written-local-variables:
            access WV_VeDMIR_Pct_HV_BatSOCTarget_write_IRV: accessed-variable=VeDMIR_Pct_HV_BatSOCTarget_write_IRV
            access WV_VeDMIR_b_HV_BatSOCTargetFA_write_IRV: accessed-variable=VeDMIR_b_HV_BatSOCTargetFA_write_IRV
        PokeDMIR_Pct_HV_BatSOCTarget_GGGC
          written-local-variables:
            access WV_VeDMIR_Pct_HV_BatSOCTarget_GGGC_write_IRV: accessed-variable=VeDMIR_Pct_HV_BatSOCTarget_GGGC_write_IRV
            access WV_VeDMIR_b_HV_BatSOCTarget_GGGCFA_write_IRV: accessed-variable=VeDMIR_b_HV_BatSOCTarget_GGGCFA_write_IRV
        PokeDMIR_Pct_PanelIntensity
          written-local-variables:
            access WV_VeDMIR_Pct_PanelIntensity_write_IRV: accessed-variable=VeDMIR_Pct_PanelIntensity_write_IRV
            access WV_VeDMIR_b_PanelIntensityFA_write_IRV: accessed-variable=VeDMIR_b_PanelIntensityFA_write_IRV
        PokeDMIR_b_DrvMdReqErr
          written-local-variables:
            access WV_VeDMIR_b_DrvMdReqErr_write_IRV: accessed-variable=VeDMIR_b_DrvMdReqErr_write_IRV
        PokeDMIR_b_ESCOffActv
          written-local-variables:
            access WV_VeDMIR_b_ESCOffActv_write_IRV: accessed-variable=VeDMIR_b_ESCOffActv_write_IRV
        PokeDMIR_b_InternalLightSts
          written-local-variables:
            access WV_VeDMIR_b_InternalLightSts_write_IRV: accessed-variable=VeDMIR_b_InternalLightSts_write_IRV
        PokeDMIR_b_PaddlesFailSts
          written-local-variables:
            access WV_VeDMIR_b_PaddlesFailStsFA_write_IRV: accessed-variable=VeDMIR_b_PaddlesFailStsFA_write_IRV
            access WV_VeDMIR_b_PaddlesFailSts_write_IRV: accessed-variable=VeDMIR_b_PaddlesFailSts_write_IRV
        PokeDMIR_b_SailOff_Request
          written-local-variables:
            access WV_VeDMIR_b_SailOff_Request_write_IRV: accessed-variable=VeDMIR_b_SailOff_Request_write_IRV
        PokeDMIR_b_SportStatus
          written-local-variables:
            access WV_VeDMIR_b_SportStatus_write_IRV: accessed-variable=VeDMIR_b_SportStatus_write_IRV
        PokeDMIR_e_BrakingMdReq
          written-local-variables:
            access WV_Comm_e_KeDMIR_e_BrakingMdReq_write_IRV: accessed-variable=Comm_e_KeDMIR_e_BrakingMdReq_write_IRV
        PokeDMIR_e_CFGFeature
          written-local-variables:
            access WV_VeDMIR_e_CFGFeature_write_IRV: accessed-variable=VeDMIR_e_CFGFeature_write_IRV
        PokeDMIR_e_CFG_Set
          written-local-variables:
            access WV_VeDMIR_e_CFG_Set_write_IRV: accessed-variable=VeDMIR_e_CFG_Set_write_IRV
        PokeDMIR_e_CreepSts
          data-send-points:
            access OUT_VeDMIR_e_CreepSts_Value: accessed-variable=VeDMIR_e_CreepSts.Value
        PokeDMIR_e_DrvMdDrvrInput
          written-local-variables:
            access WV_VeDMIR_b_DrvMdDrvrInputFA_write_IRV: accessed-variable=VeDMIR_b_DrvMdDrvrInputFA_write_IRV
            access WV_VeDMIR_e_DrvMdDrvrInput_write_IRV: accessed-variable=VeDMIR_e_DrvMdDrvrInput_write_IRV
        PokeDMIR_e_EChargetype
          written-local-variables:
            access WV_VeDMIR_b_EChargetypeFA_write_IRV: accessed-variable=VeDMIR_b_EChargetypeFA_write_IRV
            access WV_VeDMIR_e_EChargetype_write_IRV: accessed-variable=VeDMIR_e_EChargetype_write_IRV
        PokeDMIR_e_EChargetype_GGGC
          written-local-variables:
            access WV_VeDMIR_b_EChargetypeGGGCFA_write_IRV: accessed-variable=VeDMIR_b_EChargetypeGGGCFA_write_IRV
            access WV_VeDMIR_e_EChargetypeGGGC_write_IRV: accessed-variable=VeDMIR_e_EChargetypeGGGC_write_IRV
        PokeDMIR_e_ECoastingReq
          written-local-variables:
            access WV_VeDMIR_e_ECoastingReq_IRV: accessed-variable=VeDMIR_e_ECoastingReq_IRV
        PokeDMIR_e_EcoBtnSt
          written-local-variables:
            access WV_VeDMIR_b_EcoBtnStFA_write_IRV: accessed-variable=VeDMIR_b_EcoBtnStFA_write_IRV
            access WV_VeDMIR_e_EcoBtnSt_write_IRV: accessed-variable=VeDMIR_e_EcoBtnSt_write_IRV
        PokeDMIR_e_EcoBtnStLIN
          written-local-variables:
            access WV_VeDMIR_b_EcoBtnStLINFA_write_IRV: accessed-variable=VeDMIR_b_EcoBtnStLINFA_write_IRV
            access WV_VeDMIR_e_EcoBtnStLIN_write_IRV: accessed-variable=VeDMIR_e_EcoBtnStLIN_write_IRV
        PokeDMIR_e_ElectricPlusSwitch
          written-local-variables:
            access WV_VeDMIR_b_EVBtnStFA_write_IRV: accessed-variable=VeDMIR_b_EVBtnStFA_write_IRV
            access WV_VeDMIR_e_ElectricPlusSwitch_write_IRV: accessed-variable=VeDMIR_e_ElectricPlusSwitch_write_IRV
        PokeDMIR_e_ElectricPlusSwitchLIN
          written-local-variables:
            access WV_VeDMIR_b_ElectricPlusSwitchLINFA_write_IRV: accessed-variable=VeDMIR_b_ElectricPlusSwitchLINFA_write_IRV
            access WV_VeDMIR_e_ElectricPlusSwitchLIN_write_IRV: accessed-variable=VeDMIR_e_ElectricPlusSwitchLIN_write_IRV
        PokeDMIR_e_PaddleModeReq
          written-local-variables:
            access WV_VeDMIR_e_PddlMdReq_IRV: accessed-variable=VeDMIR_e_PddlMdReq_IRV
        PokeDMIR_e_PaddlesSts
          written-local-variables:
            access WV_VeDMIR_b_PaddlesStsFA_write_IRV: accessed-variable=VeDMIR_b_PaddlesStsFA_write_IRV
            access WV_VeDMIR_e_PaddleSts_write_IRV: accessed-variable=VeDMIR_e_PaddleSts_write_IRV
        PokeDMIR_e_PowershotSts
          written-local-variables:
            access WV_VeDMIR_e_PoweshotSts_IRV: accessed-variable=VeDMIR_e_PoweshotSts_IRV
        PokeDMIR_e_StReq
          written-local-variables:
            access WV_VeDMIR_e_StReq_write_IRV: accessed-variable=VeDMIR_e_StReq_write_IRV
        PokeDMIR_e_eDriveModeSwitchRqst
          written-local-variables:
            access WV_VeDMIR_b_eDriveModeSwitchRqstFA_write_IRV: accessed-variable=VeDMIR_b_eDriveModeSwitchRqstFA_write_IRV
            access WV_VeDMIR_e_eDriveModeSwitchRqst_write_IRV: accessed-variable=VeDMIR_e_eDriveModeSwitchRqst_write_IRV
        PokeDMIR_e_eSaveSwitch
          written-local-variables:
            access WV_VeDMIR_b_ESaveBtnStFA_write_IRV: accessed-variable=VeDMIR_b_ESaveBtnStFA_write_IRV
            access WV_VeDMIR_e_eSaveSwitch_write_IRV: accessed-variable=VeDMIR_e_eSaveSwitch_write_IRV
        PokeDMIR_e_eSaveSwitchLIN
          written-local-variables:
            access WV_VeDMIR_b_ESaveBtnSt_CANFA_write_IRV: accessed-variable=VeDMIR_b_ESaveBtnSt_CANFA_write_IRV
            access WV_VeDMIR_e_ESaveBtnStLIN_write_IRV: accessed-variable=VeDMIR_e_ESaveBtnStLIN_write_IRV
      9 x variation point proxy, all with category=CONDITION:
        Variant_DMIR_1: condition-access=0
        Variant_DMIR_11: condition-access=0
        Variant_DMIR_13: condition-access=0
        Variant_DMIR_15: condition-access=1
        Variant_DMIR_2: condition-access=1
        Variant_DMIR_3: condition-access=1
        Variant_DMIR_5: condition-access=0
        Variant_DMIR_7: condition-access=0
        Variant_DMIR_9: condition-access=0
